VERSION ""

NS_ :

BS_:

BU_:

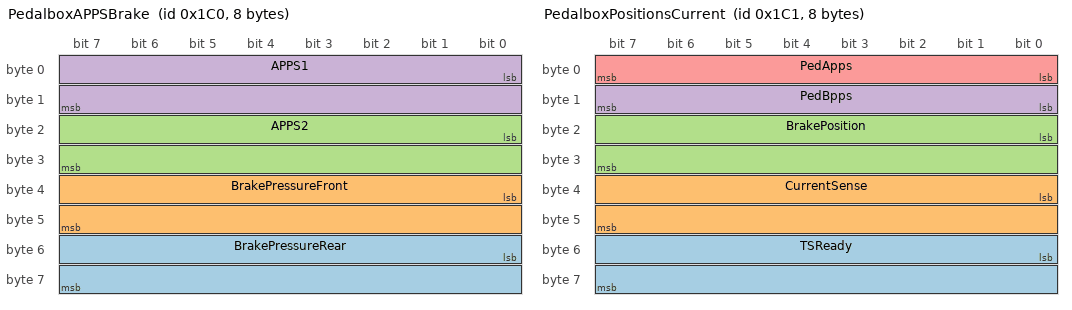
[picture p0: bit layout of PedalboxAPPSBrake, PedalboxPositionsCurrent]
BO_ 448 PedalboxAPPSBrake: 8 Vector__XXX
 SG_ BrakePressureRear : 48|16@1+ (0.001,0) [0|0] "V" Vector__XXX
 SG_ BrakePressureFront : 32|16@1+ (0.001,0) [0|0] "V" Vector__XXX
 SG_ APPS2 : 16|16@1+ (0.001,0) [0|0] "V" Vector__XXX
 SG_ APPS1 : 0|16@1+ (0.001,0) [0|0] "V" Vector__XXX

BO_ 449 PedalboxPositionsCurrent: 8 Vector__XXX
 SG_ TSReady : 48|16@1+ (0.001,0) [0|0] "V" Vector__XXX
 SG_ CurrentSense : 32|16@1+ (0.001,0) [0|0] "V" Vector__XXX
 SG_ BrakePosition : 16|16@1+ (0.001,0) [0|0] "V" Vector__XXX
 SG_ PedBpps : 8|8@1+ (1,0) [0|0] "%" Vector__XXX
 SG_ PedApps : 0|8@1+ (1,0) [0|0] "%" Vector__XXX

BO_ 450 PedalboxFaults: 8 Vector__XXX
 SG_ BrakeDrag : 16|8@1+ (1,0) [0|0] "" Vector__XXX
 SG_ HARDBRAKETHRESHOLD : 15|1@1+ (1,0) [0|0] "" Vector__XXX
 SG_ APPSANDBRAKE : 14|1@1+ (1,0) [0|0] "" Vector__XXX
 SG_ APPSIMPLAUS : 13|1@1+ (1,0) [0|0] "" Vector__XXX
 SG_ BRAKELIGHT : 12|1@1+ (1,0) [0|0] "" Vector__XXX
 SG_ BSPDHARDWARE : 11|1@1+ (1,0) [0|0] "" Vector__XXX
 SG_ BSPDOK : 10|1@1+ (1,0) [0|0] "" Vector__XXX
 SG_ CURRUV : 9|1@1+ (1,0) [0|0] "" Vector__XXX
 SG_ CURROV : 8|1@1+ (1,0) [0|0] "" Vector__XXX
 SG_ BPRUV : 7|1@1+ (1,0) [0|0] "" Vector__XXX
 SG_ BPROV : 6|1@1+ (1,0) [0|0] "" Vector__XXX
 SG_ BPFUV : 5|1@1+ (1,0) [0|0] "" Vector__XXX
 SG_ BPFOV : 4|1@1+ (1,0) [0|0] "" Vector__XXX
 SG_ APPS2UV : 3|1@1+ (1,0) [0|0] "" Vector__XXX
 SG_ APPS2OV : 2|1@1+ (1,0) [0|0] "" Vector__XXX
 SG_ APPS1UV : 1|1@1+ (1,0) [0|0] "" Vector__XXX
 SG_ APPS1OV : 0|1@1+ (1,0) [0|0] "" Vector__XXX

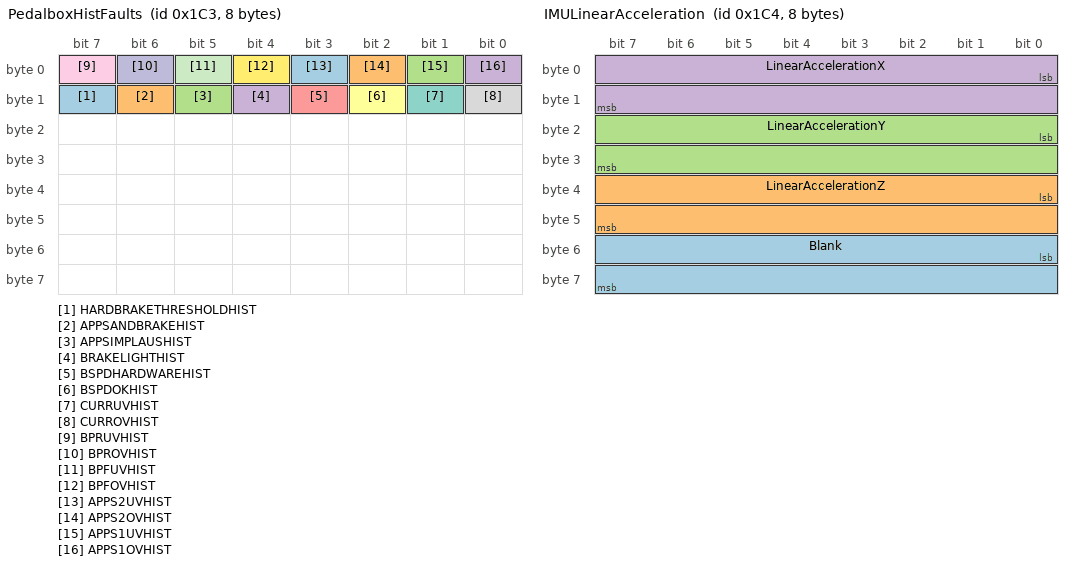
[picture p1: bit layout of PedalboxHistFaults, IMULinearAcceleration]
BO_ 451 PedalboxHistFaults: 8 Vector__XXX
 SG_ HARDBRAKETHRESHOLDHIST : 15|1@1+ (1,0) [0|0] "" Vector__XXX
 SG_ APPSANDBRAKEHIST : 14|1@1+ (1,0) [0|0] "" Vector__XXX
 SG_ APPSIMPLAUSHIST : 13|1@1+ (1,0) [0|0] "" Vector__XXX
 SG_ BRAKELIGHTHIST : 12|1@1+ (1,0) [0|0] "" Vector__XXX
 SG_ BSPDHARDWAREHIST : 11|1@1+ (1,0) [0|0] "" Vector__XXX
 SG_ BSPDOKHIST : 10|1@1+ (1,0) [0|0] "" Vector__XXX
 SG_ CURRUVHIST : 9|1@1+ (1,0) [0|0] "" Vector__XXX
 SG_ CURROVHIST : 8|1@1+ (1,0) [0|0] "" Vector__XXX
 SG_ BPRUVHIST : 7|1@1+ (1,0) [0|0] "" Vector__XXX
 SG_ BPROVHIST : 6|1@1+ (1,0) [0|0] "" Vector__XXX
 SG_ BPFUVHIST : 5|1@1+ (1,0) [0|0] "" Vector__XXX
 SG_ BPFOVHIST : 4|1@1+ (1,0) [0|0] "" Vector__XXX
 SG_ APPS2UVHIST : 3|1@1+ (1,0) [0|0] "" Vector__XXX
 SG_ APPS2OVHIST : 2|1@1+ (1,0) [0|0] "" Vector__XXX
 SG_ APPS1UVHIST : 1|1@1+ (1,0) [0|0] "" Vector__XXX
 SG_ APPS1OVHIST : 0|1@1+ (1,0) [0|0] "" Vector__XXX

BO_ 452 IMULinearAcceleration: 8 Vector__XXX
 SG_ Blank : 48|16@1- (1,0) [0|0] "" Vector__XXX
 SG_ LinearAccelerationZ : 32|16@1- (0.001,0) [0|0] "g" Vector__XXX
 SG_ LinearAccelerationY : 16|16@1- (0.001,0) [0|0] "g" Vector__XXX
 SG_ LinearAccelerationX : 0|16@1- (0.001,0) [0|0] "g" Vector__XXX

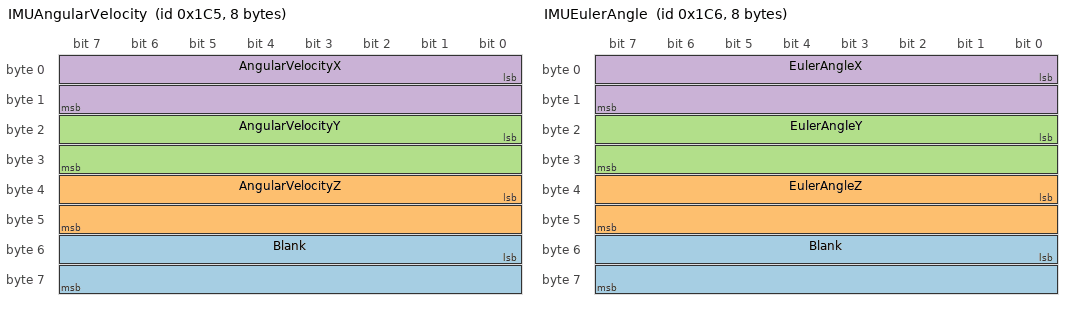
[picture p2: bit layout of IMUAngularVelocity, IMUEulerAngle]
BO_ 453 IMUAngularVelocity: 8 Vector__XXX
 SG_ Blank : 48|16@1- (1,0) [0|0] "" Vector__XXX
 SG_ AngularVelocityZ : 32|16@1- (0.1,0) [0|0] "dps" Vector__XXX
 SG_ AngularVelocityY : 16|16@1- (0.1,0) [0|0] "dps" Vector__XXX
 SG_ AngularVelocityX : 0|16@1- (0.1,0) [0|0] "dps" Vector__XXX

BO_ 454 IMUEulerAngle: 8 Vector__XXX
 SG_ Blank : 48|16@1- (1,0) [0|0] "" Vector__XXX
 SG_ EulerAngleZ : 32|16@1- (0.01,0) [0|0] "deg" Vector__XXX
 SG_ EulerAngleY : 16|16@1- (0.01,0) [0|0] "deg" Vector__XXX
 SG_ EulerAngleX : 0|16@1- (0.01,0) [0|0] "deg" Vector__XXX

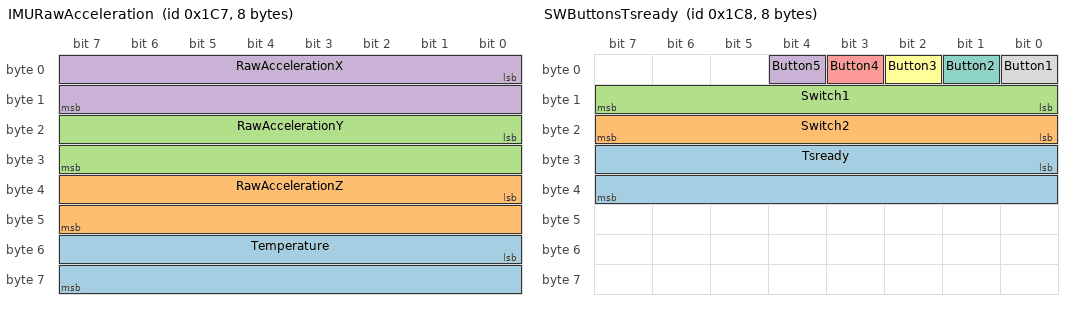
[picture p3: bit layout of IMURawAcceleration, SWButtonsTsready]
BO_ 455 IMURawAcceleration: 8 Vector__XXX
 SG_ Temperature : 48|16@1- (0.01,0) [0|0] "DegC" Vector__XXX
 SG_ RawAccelerationZ : 32|16@1- (0.001,0) [0|0] "g" Vector__XXX
 SG_ RawAccelerationY : 16|16@1- (0.001,0) [0|0] "g" Vector__XXX
 SG_ RawAccelerationX : 0|16@1- (0.001,0) [0|0] "g" Vector__XXX

BO_ 456 SWButtonsTsready: 8 Vector__XXX
 SG_ Tsready : 24|16@1+ (0.001,0) [0|0] "V" Vector__XXX
 SG_ Switch2 : 16|8@1- (1,0) [0|0] "" Vector__XXX
 SG_ Switch1 : 8|8@1- (1,0) [0|0] "" Vector__XXX
 SG_ Button5 : 4|1@1+ (1,0) [0|0] "" Vector__XXX
 SG_ Button4 : 3|1@1+ (1,0) [0|0] "" Vector__XXX
 SG_ Button3 : 2|1@1+ (1,0) [0|0] "" Vector__XXX
 SG_ Button2 : 1|1@1+ (1,0) [0|0] "" Vector__XXX
 SG_ Button1 : 0|1@1+ (1,0) [0|0] "" Vector__XXX

BO_ 457 LVMVoltageSOC: 8 Vector__XXX
 SG_ SOCEstimate : 48|16@1+ (0.1,0) [0|0] "%" Vector__XXX
 SG_ HighestTemp : 32|16@1+ (0.01,0) [0|0] "DegC" Vector__XXX
 SG_ BMSVoltage : 0|32@1+ (0.1,0) [0|0] "mV" Vector__XXX

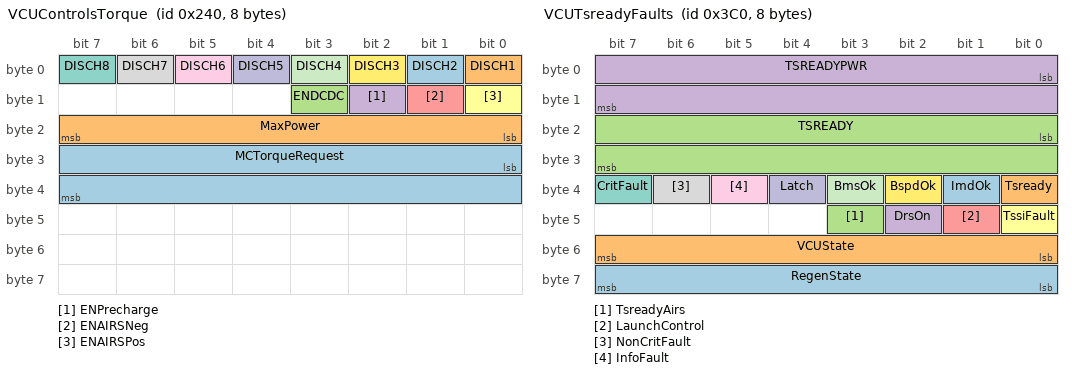
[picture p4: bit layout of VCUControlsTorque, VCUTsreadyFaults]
BO_ 576 VCUControlsTorque: 8 Vector__XXX
 SG_ MCTorqueRequest : 24|16@1- (0.1,0) [0|0] "Nm" Vector__XXX
 SG_ MaxPower : 16|8@1+ (1000,0) [0|0] "W" Vector__XXX
 SG_ ENDCDC : 11|1@1+ (1,0) [0|0] "" Vector__XXX
 SG_ ENPrecharge : 10|1@1+ (1,0) [0|0] "" Vector__XXX
 SG_ ENAIRSNeg : 9|1@1+ (1,0) [0|0] "" Vector__XXX
 SG_ ENAIRSPos : 8|1@1+ (1,0) [0|0] "" Vector__XXX
 SG_ DISCH8 : 7|1@1+ (1,0) [0|0] "" Vector__XXX
 SG_ DISCH7 : 6|1@1+ (1,0) [0|0] "" Vector__XXX
 SG_ DISCH6 : 5|1@1+ (1,0) [0|0] "" Vector__XXX
 SG_ DISCH5 : 4|1@1+ (1,0) [0|0] "" Vector__XXX
 SG_ DISCH4 : 3|1@1+ (1,0) [0|0] "" Vector__XXX
 SG_ DISCH3 : 2|1@1+ (1,0) [0|0] "" Vector__XXX
 SG_ DISCH2 : 1|1@1+ (1,0) [0|0] "" Vector__XXX
 SG_ DISCH1 : 0|1@1+ (1,0) [0|0] "" Vector__XXX

BO_ 960 VCUTsreadyFaults: 8 Vector__XXX
 SG_ RegenState : 56|8@1+ (1,0) [0|0] "" Vector__XXX
 SG_ VCUState : 48|8@1- (1,0) [0|0] "" Vector__XXX
 SG_ TsreadyAirs : 43|1@1+ (1,0) [0|0] "" Vector__XXX
 SG_ DrsOn : 42|1@1+ (1,0) [0|0] "" Vector__XXX
 SG_ LaunchControl : 41|1@1+ (1,0) [0|0] "" Vector__XXX
 SG_ TssiFault : 40|1@1+ (1,0) [0|0] "" Vector__XXX
 SG_ CritFault : 39|1@1+ (1,0) [0|0] "" Vector__XXX
 SG_ NonCritFault : 38|1@1+ (1,0) [0|0] "" Vector__XXX
 SG_ InfoFault : 37|1@1+ (1,0) [0|0] "" Vector__XXX
 SG_ Latch : 36|1@1+ (1,0) [0|0] "" Vector__XXX
 SG_ BmsOk : 35|1@1+ (1,0) [0|0] "" Vector__XXX
 SG_ BspdOk : 34|1@1+ (1,0) [0|0] "" Vector__XXX
 SG_ ImdOk : 33|1@1+ (1,0) [0|0] "" Vector__XXX
 SG_ Tsready : 32|1@1+ (1,0) [0|0] "" Vector__XXX
 SG_ TSREADY : 16|16@1+ (0.001,0) [0|0] "V" Vector__XXX
 SG_ TSREADYPWR : 0|16@1+ (0.001,0) [0|0] "V" Vector__XXX

VAL_ 960 VCUState 0 "IDLE" 1 "PRECHARGE" 2 "AIRS_CLOSED" 3 "DRIVE" ;

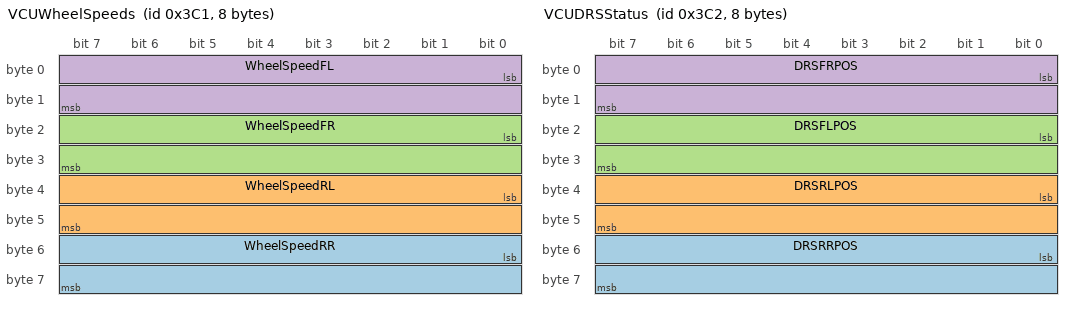
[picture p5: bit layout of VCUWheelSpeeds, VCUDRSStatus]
BO_ 961 VCUWheelSpeeds: 8 Vector__XXX
 SG_ WheelSpeedRR : 48|16@1+ (0.1,0) [0|0] "rpm" Vector__XXX
 SG_ WheelSpeedRL : 32|16@1+ (0.1,0) [0|0] "rpm" Vector__XXX
 SG_ WheelSpeedFR : 16|16@1+ (0.1,0) [0|0] "rpm" Vector__XXX
 SG_ WheelSpeedFL : 0|16@1+ (0.1,0) [0|0] "rpm" Vector__XXX

BO_ 962 VCUDRSStatus: 8 Vector__XXX
 SG_ DRSRRPOS : 48|16@1+ (0.1,0) [0|0] "Deg" Vector__XXX
 SG_ DRSRLPOS : 32|16@1+ (0.1,0) [0|0] "Deg" Vector__XXX
 SG_ DRSFLPOS : 16|16@1+ (0.1,0) [0|0] "Deg" Vector__XXX
 SG_ DRSFRPOS : 0|16@1+ (0.1,0) [0|0] "Deg" Vector__XXX

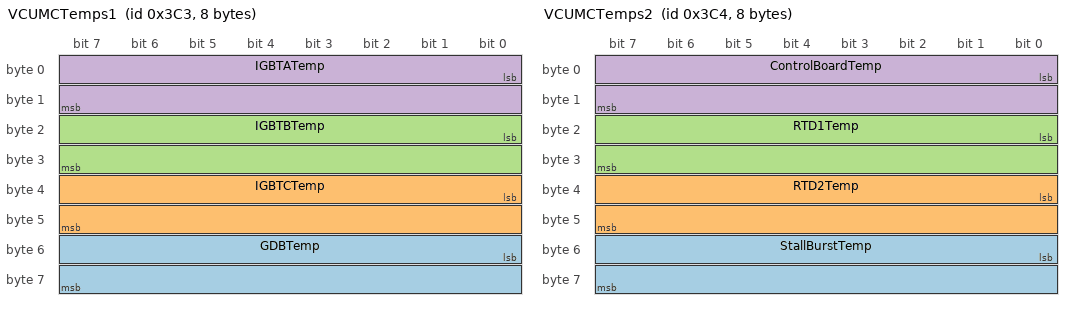
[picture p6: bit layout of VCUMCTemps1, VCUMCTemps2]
BO_ 963 VCUMCTemps1: 8 Vector__XXX
 SG_ GDBTemp : 48|16@1- (0.1,0) [0|0] "DegC" Vector__XXX
 SG_ IGBTCTemp : 32|16@1- (0.1,0) [0|0] "DegC" Vector__XXX
 SG_ IGBTBTemp : 16|16@1- (0.1,0) [0|0] "DegC" Vector__XXX
 SG_ IGBTATemp : 0|16@1- (0.1,0) [0|0] "DegC" Vector__XXX

BO_ 964 VCUMCTemps2: 8 Vector__XXX
 SG_ StallBurstTemp : 48|16@1- (0.1,0) [0|0] "DegC" Vector__XXX
 SG_ RTD2Temp : 32|16@1- (0.1,0) [0|0] "DegC" Vector__XXX
 SG_ RTD1Temp : 16|16@1- (0.1,0) [0|0] "DegC" Vector__XXX
 SG_ ControlBoardTemp : 0|16@1- (0.1,0) [0|0] "DegC" Vector__XXX

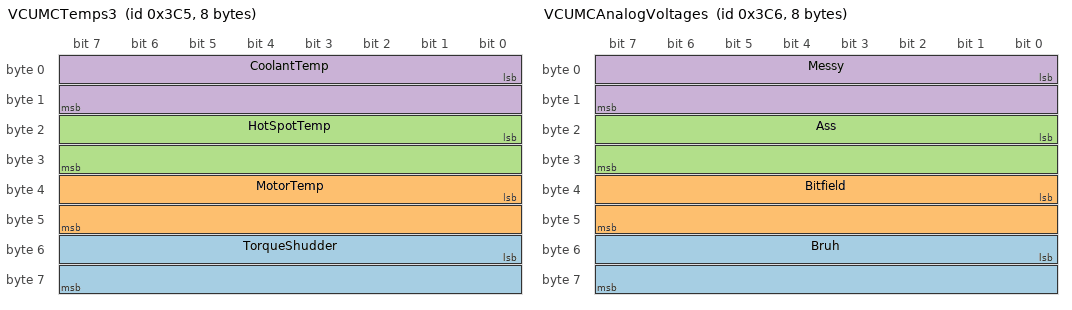
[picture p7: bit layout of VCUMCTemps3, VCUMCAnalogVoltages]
BO_ 965 VCUMCTemps3: 8 Vector__XXX
 SG_ TorqueShudder : 48|16@1- (1,0) [0|0] "" Vector__XXX
 SG_ MotorTemp : 32|16@1- (0.1,0) [0|0] "DegC" Vector__XXX
 SG_ HotSpotTemp : 16|16@1- (0.1,0) [0|0] "DegC" Vector__XXX
 SG_ CoolantTemp : 0|16@1- (0.1,0) [0|0] "DegC" Vector__XXX

BO_ 966 VCUMCAnalogVoltages: 8 Vector__XXX
 SG_ Bruh : 48|16@1+ (1,0) [0|0] "" Vector__XXX
 SG_ Bitfield : 32|16@1+ (1,0) [0|0] "" Vector__XXX
 SG_ Ass : 16|16@1+ (1,0) [0|0] "" Vector__XXX
 SG_ Messy : 0|16@1+ (1,0) [0|0] "" Vector__XXX

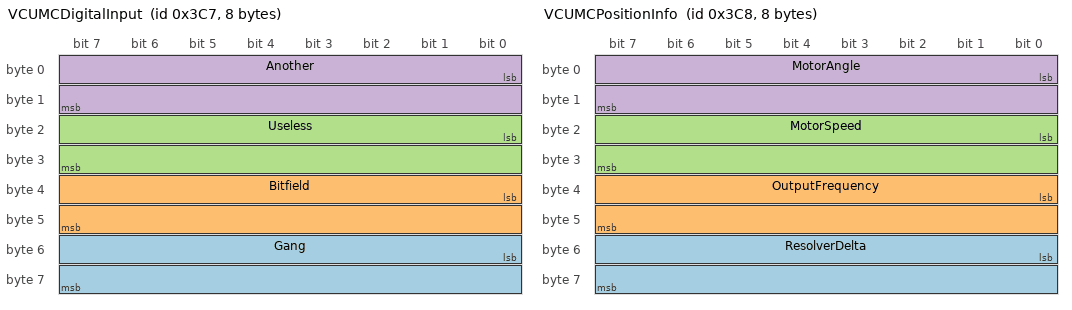
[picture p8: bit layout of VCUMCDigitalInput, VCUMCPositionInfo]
BO_ 967 VCUMCDigitalInput: 8 Vector__XXX
 SG_ Gang : 48|16@1+ (1,0) [0|0] "" Vector__XXX
 SG_ Bitfield : 32|16@1+ (1,0) [0|0] "" Vector__XXX
 SG_ Useless : 16|16@1+ (1,0) [0|0] "" Vector__XXX
 SG_ Another : 0|16@1+ (1,0) [0|0] "" Vector__XXX

BO_ 968 VCUMCPositionInfo: 8 Vector__XXX
 SG_ ResolverDelta : 48|16@1- (0.1,0) [0|0] "Deg" Vector__XXX
 SG_ OutputFrequency : 32|16@1- (0.1,0) [0|0] "Hz" Vector__XXX
 SG_ MotorSpeed : 16|16@1- (1,0) [0|0] "rpm" Vector__XXX
 SG_ MotorAngle : 0|16@1- (0.1,0) [0|0] "Deg" Vector__XXX

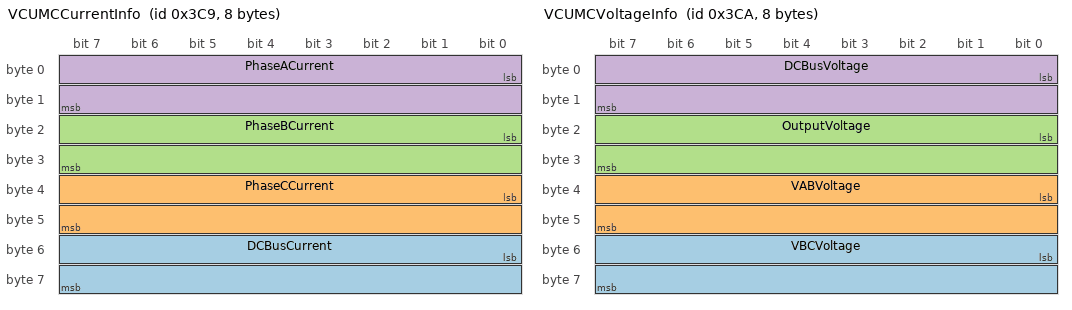
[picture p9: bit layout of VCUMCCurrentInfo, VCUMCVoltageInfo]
BO_ 969 VCUMCCurrentInfo: 8 Vector__XXX
 SG_ DCBusCurrent : 48|16@1- (0.1,0) [0|0] "A" Vector__XXX
 SG_ PhaseCCurrent : 32|16@1- (0.1,0) [0|0] "A" Vector__XXX
 SG_ PhaseBCurrent : 16|16@1- (0.1,0) [0|0] "A" Vector__XXX
 SG_ PhaseACurrent : 0|16@1- (0.1,0) [0|0] "A" Vector__XXX

BO_ 970 VCUMCVoltageInfo: 8 Vector__XXX
 SG_ VBCVoltage : 48|16@1- (0.1,0) [0|0] "V" Vector__XXX
 SG_ VABVoltage : 32|16@1- (0.1,0) [0|0] "V" Vector__XXX
 SG_ OutputVoltage : 16|16@1- (0.1,0) [0|0] "V" Vector__XXX
 SG_ DCBusVoltage : 0|16@1- (0.1,0) [0|0] "V" Vector__XXX

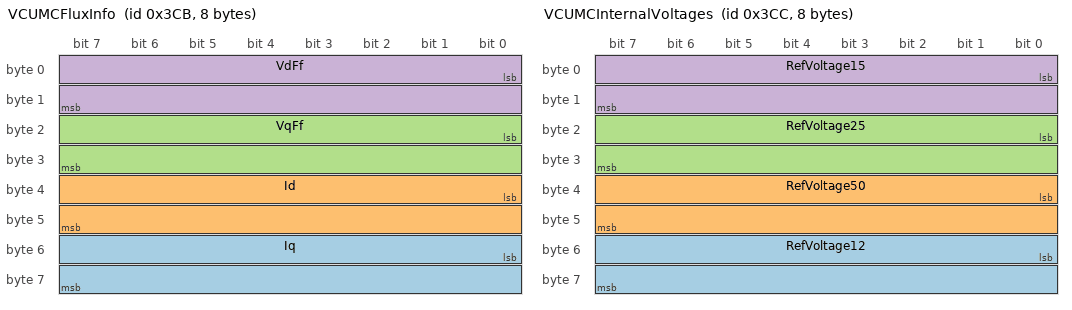
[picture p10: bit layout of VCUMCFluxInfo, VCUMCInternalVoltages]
BO_ 971 VCUMCFluxInfo: 8 Vector__XXX
 SG_ Iq : 48|16@1- (0.1,0) [0|0] "A" Vector__XXX
 SG_ Id : 32|16@1- (0.1,0) [0|0] "A" Vector__XXX
 SG_ VqFf : 16|16@1- (0.001,0) [0|0] "W" Vector__XXX
 SG_ VdFf : 0|16@1- (0.001,0) [0|0] "W" Vector__XXX

BO_ 972 VCUMCInternalVoltages: 8 Vector__XXX
 SG_ RefVoltage12 : 48|16@1- (0.01,0) [0|0] "V" Vector__XXX
 SG_ RefVoltage50 : 32|16@1- (0.01,0) [0|0] "V" Vector__XXX
 SG_ RefVoltage25 : 16|16@1- (0.01,0) [0|0] "V" Vector__XXX
 SG_ RefVoltage15 : 0|16@1- (0.01,0) [0|0] "V" Vector__XXX

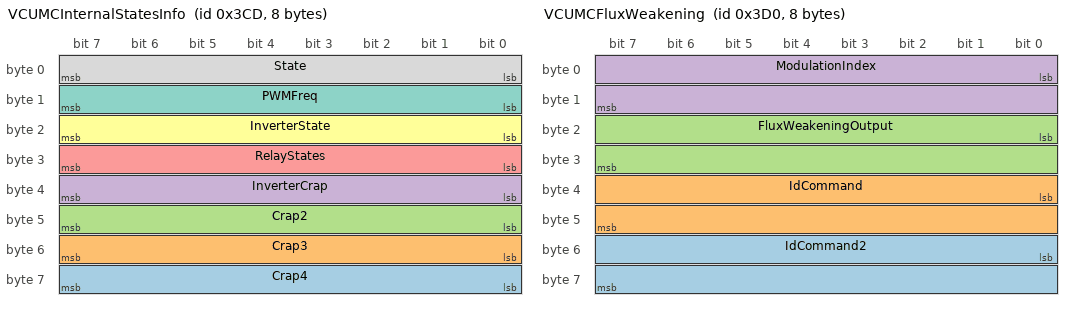
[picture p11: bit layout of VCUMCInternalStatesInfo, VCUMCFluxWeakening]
BO_ 973 VCUMCInternalStatesInfo: 8 Vector__XXX
 SG_ Crap4 : 56|8@1+ (1,0) [0|0] "" Vector__XXX
 SG_ Crap3 : 48|8@1+ (1,0) [0|0] "" Vector__XXX
 SG_ Crap2 : 40|8@1+ (1,0) [0|0] "" Vector__XXX
 SG_ InverterCrap : 32|8@1+ (1,0) [0|0] "" Vector__XXX
 SG_ RelayStates : 24|8@1+ (1,0) [0|0] "" Vector__XXX
 SG_ InverterState : 16|8@1+ (1,0) [0|0] "" Vector__XXX
 SG_ PWMFreq : 8|8@1+ (1000,0) [0|0] "Hz" Vector__XXX
 SG_ State : 0|8@1+ (1,0) [0|0] "" Vector__XXX

BO_ 974 VCUMCFaultCodes: 8 Vector__XXX
 SG_ RunFaults : 32|32@1+ (1,0) [0|0] "" Vector__XXX
 SG_ PostFaults : 0|32@1+ (1,0) [0|0] "" Vector__XXX

BO_ 975 VCUMCTorqueTimer: 8 Vector__XXX
 SG_ PowerOnTime : 32|32@1+ (1,0) [0|0] "" Vector__XXX
 SG_ TorqueFeedback : 16|16@1- (0.1,0) [0|0] "Nm" Vector__XXX
 SG_ CommandedTorque : 0|16@1- (0.1,0) [0|0] "Nm" Vector__XXX

BO_ 976 VCUMCFluxWeakening: 8 Vector__XXX
 SG_ IdCommand2 : 48|16@1- (0.1,0) [0|0] "A" Vector__XXX
 SG_ IdCommand : 32|16@1- (0.1,0) [0|0] "A" Vector__XXX
 SG_ FluxWeakeningOutput : 16|16@1- (0.1,0) [0|0] "A" Vector__XXX
 SG_ ModulationIndex : 0|16@1+ (1,0) [0|0] "" Vector__XXX

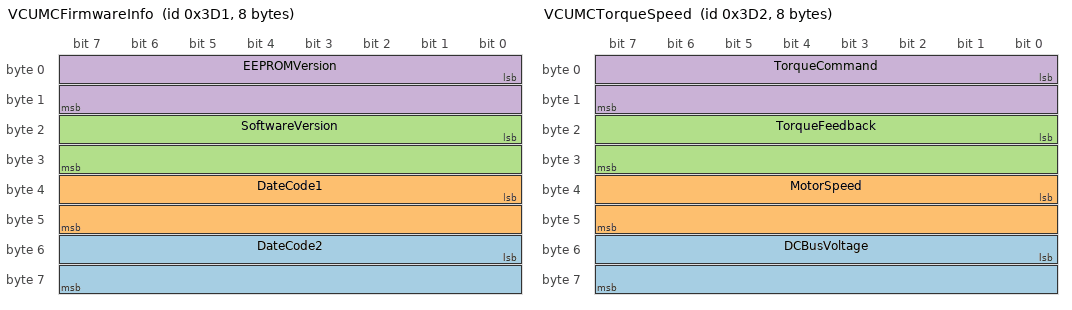
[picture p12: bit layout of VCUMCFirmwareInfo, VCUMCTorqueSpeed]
BO_ 977 VCUMCFirmwareInfo: 8 Vector__XXX
 SG_ DateCode2 : 48|16@1+ (1,0) [0|0] "" Vector__XXX
 SG_ DateCode1 : 32|16@1+ (1,0) [0|0] "" Vector__XXX
 SG_ SoftwareVersion : 16|16@1+ (1,0) [0|0] "" Vector__XXX
 SG_ EEPROMVersion : 0|16@1+ (1,0) [0|0] "" Vector__XXX

BO_ 978 VCUMCTorqueSpeed: 8 Vector__XXX
 SG_ DCBusVoltage : 48|16@1- (0.1,0) [0|0] "V" Vector__XXX
 SG_ MotorSpeed : 32|16@1- (1,0) [0|0] "rpm" Vector__XXX
 SG_ TorqueFeedback : 16|16@1- (0.1,0) [0|0] "Nm" Vector__XXX
 SG_ TorqueCommand : 0|16@1- (0.1,0) [0|0] "Nm" Vector__XXX

BO_ 979 VCUMCTorqueCapability: 8 Vector__XXX
 SG_ Unused : 32|32@1+ (1,0) [0|0] "" Vector__XXX
 SG_ AvailableRegenTorque : 16|16@1- (0.1,0) [0|0] "Nm" Vector__XXX
 SG_ AvailableTorque : 0|16@1- (0.1,0) [0|0] "Nm" Vector__XXX

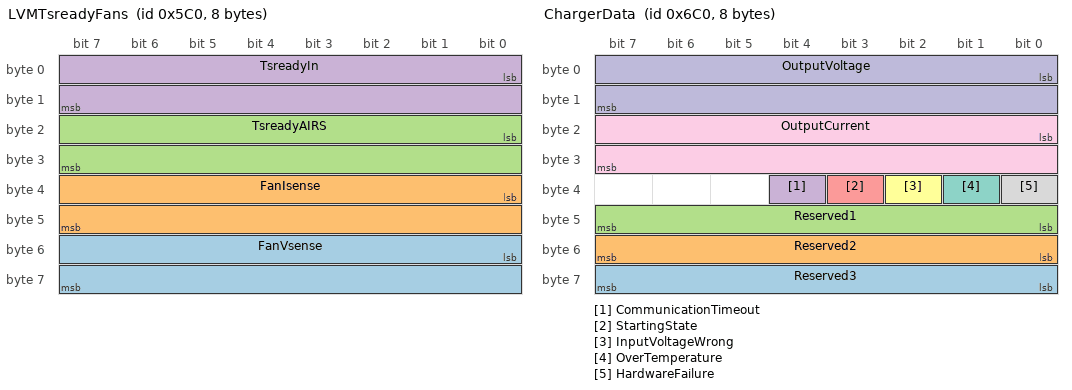
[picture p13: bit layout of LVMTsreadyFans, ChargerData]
BO_ 1472 LVMTsreadyFans: 8 Vector__XXX
 SG_ FanVsense : 48|16@1+ (0.001,0) [0|0] "V" Vector__XXX
 SG_ FanIsense : 32|16@1+ (0.001,0) [0|0] "A" Vector__XXX
 SG_ TsreadyAIRS : 16|16@1+ (0.001,0) [0|0] "V" Vector__XXX
 SG_ TsreadyIn : 0|16@1+ (0.001,0) [0|0] "V" Vector__XXX

BO_ 1728 ChargerData: 8 Vector__XXX
 SG_ Reserved3 : 56|8@1+ (1,0) [0|0] "" Vector__XXX
 SG_ Reserved2 : 48|8@1+ (1,0) [0|0] "" Vector__XXX
 SG_ Reserved1 : 40|8@1+ (1,0) [0|0] "" Vector__XXX
 SG_ CommunicationTimeout : 36|1@1+ (1,0) [0|0] "" Vector__XXX
 SG_ StartingState : 35|1@1+ (1,0) [0|0] "" Vector__XXX
 SG_ InputVoltageWrong : 34|1@1+ (1,0) [0|0] "" Vector__XXX
 SG_ OverTemperature : 33|1@1+ (1,0) [0|0] "" Vector__XXX
 SG_ HardwareFailure : 32|1@1+ (1,0) [0|0] "" Vector__XXX
 SG_ OutputCurrent : 16|16@1+ (0.1,0) [0|0] "A" Vector__XXX
 SG_ OutputVoltage : 0|16@1+ (0.1,0) [0|0] "V" Vector__XXX

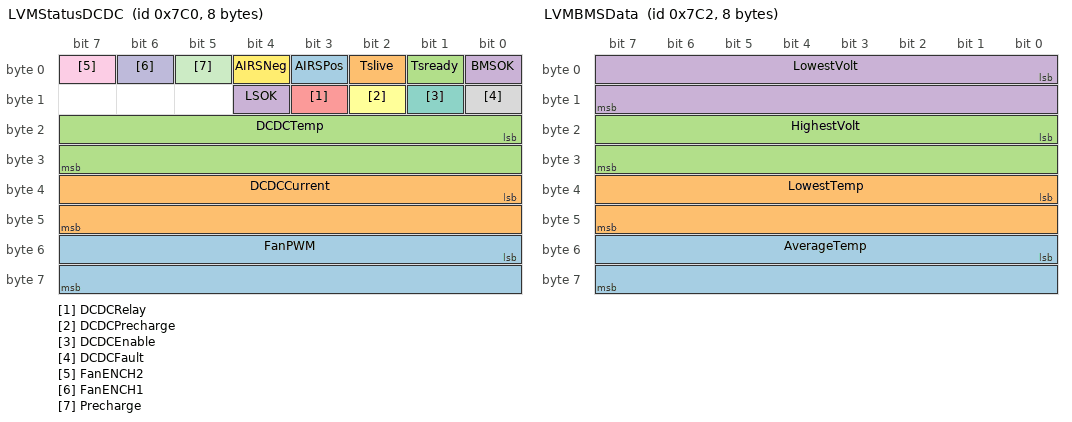
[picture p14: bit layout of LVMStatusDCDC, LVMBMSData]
BO_ 1984 LVMStatusDCDC: 8 Vector__XXX
 SG_ FanPWM : 48|16@1+ (1,0) [0|0] "%" Vector__XXX
 SG_ DCDCCurrent : 32|16@1- (0.1,0) [0|0] "A" Vector__XXX
 SG_ DCDCTemp : 16|16@1+ (0.01,0) [0|0] "DegC" Vector__XXX
 SG_ LSOK : 12|1@1+ (1,0) [0|0] "" Vector__XXX
 SG_ DCDCRelay : 11|1@1+ (1,0) [0|0] "" Vector__XXX
 SG_ DCDCPrecharge : 10|1@1+ (1,0) [0|0] "" Vector__XXX
 SG_ DCDCEnable : 9|1@1+ (1,0) [0|0] "" Vector__XXX
 SG_ DCDCFault : 8|1@1+ (1,0) [0|0] "" Vector__XXX
 SG_ FanENCH2 : 7|1@1+ (1,0) [0|0] "" Vector__XXX
 SG_ FanENCH1 : 6|1@1+ (1,0) [0|0] "" Vector__XXX
 SG_ Precharge : 5|1@1+ (1,0) [0|0] "" Vector__XXX
 SG_ AIRSNeg : 4|1@1+ (1,0) [0|0] "" Vector__XXX
 SG_ AIRSPos : 3|1@1+ (1,0) [0|0] "" Vector__XXX
 SG_ Tslive : 2|1@1+ (1,0) [0|0] "" Vector__XXX
 SG_ Tsready : 1|1@1+ (1,0) [0|0] "" Vector__XXX
 SG_ BMSOK : 0|1@1+ (1,0) [0|0] "" Vector__XXX

BO_ 1985 LVMCurrentTaskStatus: 8 Vector__XXX
 SG_ TaskStatus : 32|8@1- (1,0) [0|0] "" Vector__XXX
 SG_ Currenta : 16|16@1- (1,0) [0|0] "A" Vector__XXX
 SG_ Currentv : 0|16@1+ (0.001,0) [0|0] "V" Vector__XXX

VAL_ 1985 TaskStatus 0 "eRunning" 1 "eReady" 2 "eBlocked" 3 "eSuspended" 4 "eDeleted" 5 "eInvalid" ;

BO_ 1986 LVMBMSData: 8 Vector__XXX
 SG_ AverageTemp : 48|16@1+ (0.01,0) [0|0] "DegC" Vector__XXX
 SG_ LowestTemp : 32|16@1+ (0.01,0) [0|0] "DegC" Vector__XXX
 SG_ HighestVolt : 16|16@1+ (0.1,0) [0|0] "mV" Vector__XXX
 SG_ LowestVolt : 0|16@1+ (0.1,0) [0|0] "mV" Vector__XXX

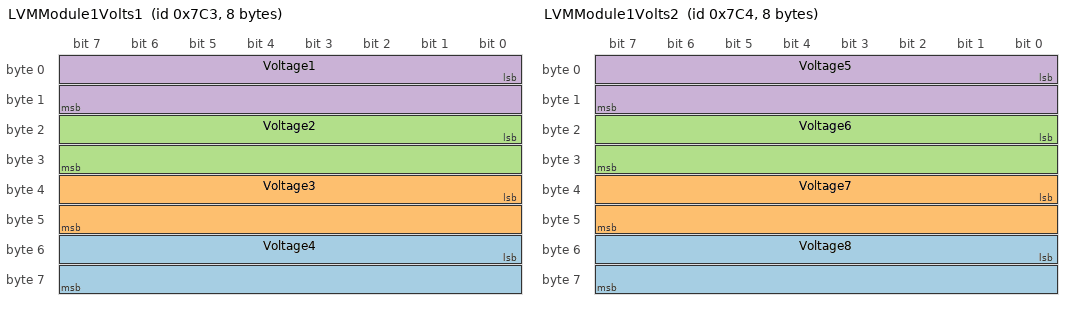
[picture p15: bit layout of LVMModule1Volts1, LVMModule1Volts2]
BO_ 1987 LVMModule1Volts1: 8 Vector__XXX
 SG_ Voltage4 : 48|16@1+ (0.1,0) [0|0] "mV" Vector__XXX
 SG_ Voltage3 : 32|16@1+ (0.1,0) [0|0] "mV" Vector__XXX
 SG_ Voltage2 : 16|16@1+ (0.1,0) [0|0] "mV" Vector__XXX
 SG_ Voltage1 : 0|16@1+ (0.1,0) [0|0] "mV" Vector__XXX

BO_ 1988 LVMModule1Volts2: 8 Vector__XXX
 SG_ Voltage8 : 48|16@1+ (0.1,0) [0|0] "mV" Vector__XXX
 SG_ Voltage7 : 32|16@1+ (0.1,0) [0|0] "mV" Vector__XXX
 SG_ Voltage6 : 16|16@1+ (0.1,0) [0|0] "mV" Vector__XXX
 SG_ Voltage5 : 0|16@1+ (0.1,0) [0|0] "mV" Vector__XXX

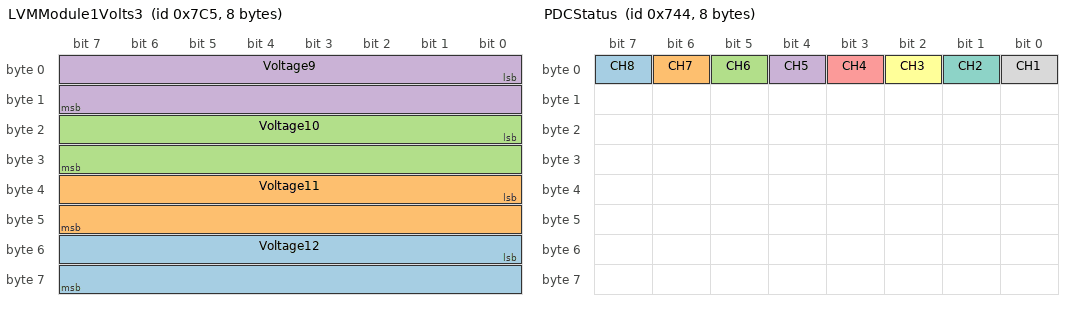
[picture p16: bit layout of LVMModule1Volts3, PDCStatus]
BO_ 1989 LVMModule1Volts3: 8 Vector__XXX
 SG_ Voltage12 : 48|16@1+ (0.1,0) [0|0] "mV" Vector__XXX
 SG_ Voltage11 : 32|16@1+ (0.1,0) [0|0] "mV" Vector__XXX
 SG_ Voltage10 : 16|16@1+ (0.1,0) [0|0] "mV" Vector__XXX
 SG_ Voltage9 : 0|16@1+ (0.1,0) [0|0] "mV" Vector__XXX

BO_ 1990 LVMModule1Volts4: 8 Vector__XXX
 SG_ Voltage16 : 48|16@1+ (0.1,0) [0|0] "mV" Vector__XXX
 SG_ Voltage15 : 32|16@1+ (0.1,0) [0|0] "mV" Vector__XXX
 SG_ Voltage14 : 16|16@1+ (0.1,0) [0|0] "mV" Vector__XXX
 SG_ Voltage13 : 0|16@1+ (0.1,0) [0|0] "mV" Vector__XXX

BO_ 1991 LVMModule2Volts1: 8 Vector__XXX
 SG_ Voltage4 : 48|16@1+ (0.1,0) [0|0] "mV" Vector__XXX
 SG_ Voltage3 : 32|16@1+ (0.1,0) [0|0] "mV" Vector__XXX
 SG_ Voltage2 : 16|16@1+ (0.1,0) [0|0] "mV" Vector__XXX
 SG_ Voltage1 : 0|16@1+ (0.1,0) [0|0] "mV" Vector__XXX

BO_ 1992 LVMModule2Volts2: 8 Vector__XXX
 SG_ Voltage8 : 48|16@1+ (0.1,0) [0|0] "mV" Vector__XXX
 SG_ Voltage7 : 32|16@1+ (0.1,0) [0|0] "mV" Vector__XXX
 SG_ Voltage6 : 16|16@1+ (0.1,0) [0|0] "mV" Vector__XXX
 SG_ Voltage5 : 0|16@1+ (0.1,0) [0|0] "mV" Vector__XXX

BO_ 1993 LVMModule2Volts3: 8 Vector__XXX
 SG_ Voltage12 : 48|16@1+ (0.1,0) [0|0] "mV" Vector__XXX
 SG_ Voltage11 : 32|16@1+ (0.1,0) [0|0] "mV" Vector__XXX
 SG_ Voltage10 : 16|16@1+ (0.1,0) [0|0] "mV" Vector__XXX
 SG_ Voltage9 : 0|16@1+ (0.1,0) [0|0] "mV" Vector__XXX

BO_ 1994 LVMModule2Volts4: 8 Vector__XXX
 SG_ Voltage16 : 48|16@1+ (0.1,0) [0|0] "mV" Vector__XXX
 SG_ Voltage15 : 32|16@1+ (0.1,0) [0|0] "mV" Vector__XXX
 SG_ Voltage14 : 16|16@1+ (0.1,0) [0|0] "mV" Vector__XXX
 SG_ Voltage13 : 0|16@1+ (0.1,0) [0|0] "mV" Vector__XXX

BO_ 1995 LVMModule3Volts1: 8 Vector__XXX
 SG_ Voltage4 : 48|16@1+ (0.1,0) [0|0] "mV" Vector__XXX
 SG_ Voltage3 : 32|16@1+ (0.1,0) [0|0] "mV" Vector__XXX
 SG_ Voltage2 : 16|16@1+ (0.1,0) [0|0] "mV" Vector__XXX
 SG_ Voltage1 : 0|16@1+ (0.1,0) [0|0] "mV" Vector__XXX

BO_ 1996 LVMModule3Volts2: 8 Vector__XXX
 SG_ Voltage8 : 48|16@1+ (0.1,0) [0|0] "mV" Vector__XXX
 SG_ Voltage7 : 32|16@1+ (0.1,0) [0|0] "mV" Vector__XXX
 SG_ Voltage6 : 16|16@1+ (0.1,0) [0|0] "mV" Vector__XXX
 SG_ Voltage5 : 0|16@1+ (0.1,0) [0|0] "mV" Vector__XXX

BO_ 1997 LVMModule3Volts3: 8 Vector__XXX
 SG_ Voltage12 : 48|16@1+ (0.1,0) [0|0] "mV" Vector__XXX
 SG_ Voltage11 : 32|16@1+ (0.1,0) [0|0] "mV" Vector__XXX
 SG_ Voltage10 : 16|16@1+ (0.1,0) [0|0] "mV" Vector__XXX
 SG_ Voltage9 : 0|16@1+ (0.1,0) [0|0] "mV" Vector__XXX

BO_ 1998 LVMModule3Volts4: 8 Vector__XXX
 SG_ Voltage16 : 48|16@1+ (0.1,0) [0|0] "mV" Vector__XXX
 SG_ Voltage15 : 32|16@1+ (0.1,0) [0|0] "mV" Vector__XXX
 SG_ Voltage14 : 16|16@1+ (0.1,0) [0|0] "mV" Vector__XXX
 SG_ Voltage13 : 0|16@1+ (0.1,0) [0|0] "mV" Vector__XXX

BO_ 1999 LVMModule4Volts1: 8 Vector__XXX
 SG_ Voltage4 : 48|16@1+ (0.1,0) [0|0] "mV" Vector__XXX
 SG_ Voltage3 : 32|16@1+ (0.1,0) [0|0] "mV" Vector__XXX
 SG_ Voltage2 : 16|16@1+ (0.1,0) [0|0] "mV" Vector__XXX
 SG_ Voltage1 : 0|16@1+ (0.1,0) [0|0] "mV" Vector__XXX

BO_ 2000 LVMModule4Volts2: 8 Vector__XXX
 SG_ Voltage8 : 48|16@1+ (0.1,0) [0|0] "mV" Vector__XXX
 SG_ Voltage7 : 32|16@1+ (0.1,0) [0|0] "mV" Vector__XXX
 SG_ Voltage6 : 16|16@1+ (0.1,0) [0|0] "mV" Vector__XXX
 SG_ Voltage5 : 0|16@1+ (0.1,0) [0|0] "mV" Vector__XXX

BO_ 2001 LVMModule4Volts3: 8 Vector__XXX
 SG_ Voltage12 : 48|16@1+ (0.1,0) [0|0] "mV" Vector__XXX
 SG_ Voltage11 : 32|16@1+ (0.1,0) [0|0] "mV" Vector__XXX
 SG_ Voltage10 : 16|16@1+ (0.1,0) [0|0] "mV" Vector__XXX
 SG_ Voltage9 : 0|16@1+ (0.1,0) [0|0] "mV" Vector__XXX

BO_ 2002 LVMModule4Volts4: 8 Vector__XXX
 SG_ Voltage16 : 48|16@1+ (0.1,0) [0|0] "mV" Vector__XXX
 SG_ Voltage15 : 32|16@1+ (0.1,0) [0|0] "mV" Vector__XXX
 SG_ Voltage14 : 16|16@1+ (0.1,0) [0|0] "mV" Vector__XXX
 SG_ Voltage13 : 0|16@1+ (0.1,0) [0|0] "mV" Vector__XXX

BO_ 2003 LVMModule5Volts1: 8 Vector__XXX
 SG_ Voltage4 : 48|16@1+ (0.1,0) [0|0] "mV" Vector__XXX
 SG_ Voltage3 : 32|16@1+ (0.1,0) [0|0] "mV" Vector__XXX
 SG_ Voltage2 : 16|16@1+ (0.1,0) [0|0] "mV" Vector__XXX
 SG_ Voltage1 : 0|16@1+ (0.1,0) [0|0] "mV" Vector__XXX

BO_ 2004 LVMModule5Volts2: 8 Vector__XXX
 SG_ Voltage8 : 48|16@1+ (0.1,0) [0|0] "mV" Vector__XXX
 SG_ Voltage7 : 32|16@1+ (0.1,0) [0|0] "mV" Vector__XXX
 SG_ Voltage6 : 16|16@1+ (0.1,0) [0|0] "mV" Vector__XXX
 SG_ Voltage5 : 0|16@1+ (0.1,0) [0|0] "mV" Vector__XXX

BO_ 2005 LVMModule5Volts3: 8 Vector__XXX
 SG_ Voltage12 : 48|16@1+ (0.1,0) [0|0] "mV" Vector__XXX
 SG_ Voltage11 : 32|16@1+ (0.1,0) [0|0] "mV" Vector__XXX
 SG_ Voltage10 : 16|16@1+ (0.1,0) [0|0] "mV" Vector__XXX
 SG_ Voltage9 : 0|16@1+ (0.1,0) [0|0] "mV" Vector__XXX

BO_ 2006 LVMModule5Volts4: 8 Vector__XXX
 SG_ Voltage16 : 48|16@1+ (0.1,0) [0|0] "mV" Vector__XXX
 SG_ Voltage15 : 32|16@1+ (0.1,0) [0|0] "mV" Vector__XXX
 SG_ Voltage14 : 16|16@1+ (0.1,0) [0|0] "mV" Vector__XXX
 SG_ Voltage13 : 0|16@1+ (0.1,0) [0|0] "mV" Vector__XXX

BO_ 2007 LVMModule6Volts1: 8 Vector__XXX
 SG_ Voltage4 : 48|16@1+ (0.1,0) [0|0] "mV" Vector__XXX
 SG_ Voltage3 : 32|16@1+ (0.1,0) [0|0] "mV" Vector__XXX
 SG_ Voltage2 : 16|16@1+ (0.1,0) [0|0] "mV" Vector__XXX
 SG_ Voltage1 : 0|16@1+ (0.1,0) [0|0] "mV" Vector__XXX

BO_ 2008 LVMModule6Volts2: 8 Vector__XXX
 SG_ Voltage8 : 48|16@1+ (0.1,0) [0|0] "mV" Vector__XXX
 SG_ Voltage7 : 32|16@1+ (0.1,0) [0|0] "mV" Vector__XXX
 SG_ Voltage6 : 16|16@1+ (0.1,0) [0|0] "mV" Vector__XXX
 SG_ Voltage5 : 0|16@1+ (0.1,0) [0|0] "mV" Vector__XXX

BO_ 2009 LVMModule6Volts3: 8 Vector__XXX
 SG_ Voltage12 : 48|16@1+ (0.1,0) [0|0] "mV" Vector__XXX
 SG_ Voltage11 : 32|16@1+ (0.1,0) [0|0] "mV" Vector__XXX
 SG_ Voltage10 : 16|16@1+ (0.1,0) [0|0] "mV" Vector__XXX
 SG_ Voltage9 : 0|16@1+ (0.1,0) [0|0] "mV" Vector__XXX

BO_ 2010 LVMModule6Volts4: 8 Vector__XXX
 SG_ Voltage16 : 48|16@1+ (0.1,0) [0|0] "mV" Vector__XXX
 SG_ Voltage15 : 32|16@1+ (0.1,0) [0|0] "mV" Vector__XXX
 SG_ Voltage14 : 16|16@1+ (0.1,0) [0|0] "mV" Vector__XXX
 SG_ Voltage13 : 0|16@1+ (0.1,0) [0|0] "mV" Vector__XXX

BO_ 2011 LVMModule1Temps1: 8 Vector__XXX
 SG_ Temp4 : 48|16@1+ (0.01,0) [0|0] "DegC" Vector__XXX
 SG_ Temp3 : 32|16@1+ (0.01,0) [0|0] "DegC" Vector__XXX
 SG_ Temp2 : 16|16@1+ (0.01,0) [0|0] "DegC" Vector__XXX
 SG_ Temp1 : 0|16@1+ (0.01,0) [0|0] "DegC" Vector__XXX

BO_ 2012 LVMModule1Temps2: 8 Vector__XXX
 SG_ Temp8 : 48|16@1+ (0.01,0) [0|0] "DegC" Vector__XXX
 SG_ Temp7 : 32|16@1+ (0.01,0) [0|0] "DegC" Vector__XXX
 SG_ Temp6 : 16|16@1+ (0.01,0) [0|0] "DegC" Vector__XXX
 SG_ Temp5 : 0|16@1+ (0.01,0) [0|0] "DegC" Vector__XXX

BO_ 2013 LVMModule1Temps3: 8 Vector__XXX
 SG_ Temp10 : 16|16@1+ (0.01,0) [0|0] "DegC" Vector__XXX
 SG_ Temp9 : 0|16@1+ (0.01,0) [0|0] "DegC" Vector__XXX

BO_ 2014 LVMModule2Temps1: 8 Vector__XXX
 SG_ Temp4 : 48|16@1+ (0.01,0) [0|0] "DegC" Vector__XXX
 SG_ Temp3 : 32|16@1+ (0.01,0) [0|0] "DegC" Vector__XXX
 SG_ Temp2 : 16|16@1+ (0.01,0) [0|0] "DegC" Vector__XXX
 SG_ Temp1 : 0|16@1+ (0.01,0) [0|0] "DegC" Vector__XXX

BO_ 2015 LVMModule2Temps2: 8 Vector__XXX
 SG_ Temp8 : 48|16@1+ (0.01,0) [0|0] "DegC" Vector__XXX
 SG_ Temp7 : 32|16@1+ (0.01,0) [0|0] "DegC" Vector__XXX
 SG_ Temp6 : 16|16@1+ (0.01,0) [0|0] "DegC" Vector__XXX
 SG_ Temp5 : 0|16@1+ (0.01,0) [0|0] "DegC" Vector__XXX

BO_ 2016 LVMModule2Temps3: 8 Vector__XXX
 SG_ Temp10 : 16|16@1+ (0.01,0) [0|0] "DegC" Vector__XXX
 SG_ Temp9 : 0|16@1+ (0.01,0) [0|0] "DegC" Vector__XXX

BO_ 2017 LVMModule3Temps1: 8 Vector__XXX
 SG_ Temp4 : 48|16@1+ (0.01,0) [0|0] "DegC" Vector__XXX
 SG_ Temp3 : 32|16@1+ (0.01,0) [0|0] "DegC" Vector__XXX
 SG_ Temp2 : 16|16@1+ (0.01,0) [0|0] "DegC" Vector__XXX
 SG_ Temp1 : 0|16@1+ (0.01,0) [0|0] "DegC" Vector__XXX

BO_ 2018 LVMModule3Temps2: 8 Vector__XXX
 SG_ Temp8 : 48|16@1+ (0.01,0) [0|0] "DegC" Vector__XXX
 SG_ Temp7 : 32|16@1+ (0.01,0) [0|0] "DegC" Vector__XXX
 SG_ Temp6 : 16|16@1+ (0.01,0) [0|0] "DegC" Vector__XXX
 SG_ Temp5 : 0|16@1+ (0.01,0) [0|0] "DegC" Vector__XXX

BO_ 2019 LVMModule3Temps3: 8 Vector__XXX
 SG_ Temp10 : 16|16@1+ (0.01,0) [0|0] "DegC" Vector__XXX
 SG_ Temp9 : 0|16@1+ (0.01,0) [0|0] "DegC" Vector__XXX

BO_ 2020 LVMModule4Temps1: 8 Vector__XXX
 SG_ Temp4 : 48|16@1+ (0.01,0) [0|0] "DegC" Vector__XXX
 SG_ Temp3 : 32|16@1+ (0.01,0) [0|0] "DegC" Vector__XXX
 SG_ Temp2 : 16|16@1+ (0.01,0) [0|0] "DegC" Vector__XXX
 SG_ Temp1 : 0|16@1+ (0.01,0) [0|0] "DegC" Vector__XXX

BO_ 2021 LVMModule4Temps2: 8 Vector__XXX
 SG_ Temp8 : 48|16@1+ (0.01,0) [0|0] "DegC" Vector__XXX
 SG_ Temp7 : 32|16@1+ (0.01,0) [0|0] "DegC" Vector__XXX
 SG_ Temp6 : 16|16@1+ (0.01,0) [0|0] "DegC" Vector__XXX
 SG_ Temp5 : 0|16@1+ (0.01,0) [0|0] "DegC" Vector__XXX

BO_ 2022 LVMModule4Temps3: 8 Vector__XXX
 SG_ Temp10 : 16|16@1+ (0.01,0) [0|0] "DegC" Vector__XXX
 SG_ Temp9 : 0|16@1+ (0.01,0) [0|0] "DegC" Vector__XXX

BO_ 2023 LVMModule5Temps1: 8 Vector__XXX
 SG_ Temp4 : 48|16@1+ (0.01,0) [0|0] "DegC" Vector__XXX
 SG_ Temp3 : 32|16@1+ (0.01,0) [0|0] "DegC" Vector__XXX
 SG_ Temp2 : 16|16@1+ (0.01,0) [0|0] "DegC" Vector__XXX
 SG_ Temp1 : 0|16@1+ (0.01,0) [0|0] "DegC" Vector__XXX

BO_ 2024 LVMModule5Temps2: 8 Vector__XXX
 SG_ Temp8 : 48|16@1+ (0.01,0) [0|0] "DegC" Vector__XXX
 SG_ Temp7 : 32|16@1+ (0.01,0) [0|0] "DegC" Vector__XXX
 SG_ Temp6 : 16|16@1+ (0.01,0) [0|0] "DegC" Vector__XXX
 SG_ Temp5 : 0|16@1+ (0.01,0) [0|0] "DegC" Vector__XXX

BO_ 2025 LVMModule5Temps3: 8 Vector__XXX
 SG_ Temp10 : 16|16@1+ (0.01,0) [0|0] "DegC" Vector__XXX
 SG_ Temp9 : 0|16@1+ (0.01,0) [0|0] "DegC" Vector__XXX

BO_ 2026 LVMModule6Temps1: 8 Vector__XXX
 SG_ Temp4 : 48|16@1+ (0.01,0) [0|0] "DegC" Vector__XXX
 SG_ Temp3 : 32|16@1+ (0.01,0) [0|0] "DegC" Vector__XXX
 SG_ Temp2 : 16|16@1+ (0.01,0) [0|0] "DegC" Vector__XXX
 SG_ Temp1 : 0|16@1+ (0.01,0) [0|0] "DegC" Vector__XXX

BO_ 2027 LVMModule6Temps2: 8 Vector__XXX
 SG_ Temp8 : 48|16@1+ (0.01,0) [0|0] "DegC" Vector__XXX
 SG_ Temp7 : 32|16@1+ (0.01,0) [0|0] "DegC" Vector__XXX
 SG_ Temp6 : 16|16@1+ (0.01,0) [0|0] "DegC" Vector__XXX
 SG_ Temp5 : 0|16@1+ (0.01,0) [0|0] "DegC" Vector__XXX

BO_ 2028 LVMModule6Temps3: 8 Vector__XXX
 SG_ Temp10 : 16|16@1+ (0.01,0) [0|0] "DegC" Vector__XXX
 SG_ Temp9 : 0|16@1+ (0.01,0) [0|0] "DegC" Vector__XXX

BO_ 1473 FrontCB1DOFPitStrpot: 8 Vector__XXX
 SG_ SteeringPot : 48|16@1+ (0.001,0) [0|0] "V" Vector__XXX
 SG_ PitotTube : 32|16@1- (1,0) [0|0] "Pa" Vector__XXX
 SG_ FL1DOF : 16|16@1+ (0.001,0) [0|0] "V" Vector__XXX
 SG_ FR1DOF : 0|16@1+ (0.001,0) [0|0] "V" Vector__XXX

BO_ 1474 FrontCBSPSG: 8 Vector__XXX
 SG_ FHShockPots : 48|16@1+ (0.001,0) [0|0] "V" Vector__XXX
 SG_ FRShockPots : 32|16@1+ (0.001,0) [0|0] "V" Vector__XXX
 SG_ FLStrainGauge : 16|16@1+ (0.001,0) [0|0] "V" Vector__XXX
 SG_ FRStrainGauge : 0|16@1+ (0.001,0) [0|0] "V" Vector__XXX

BO_ 1475 RearCBSPSG: 8 Vector__XXX
 SG_ RHShockPots : 48|16@1+ (0.001,0) [0|0] "V" Vector__XXX
 SG_ RRShockPots : 32|16@1+ (0.001,0) [0|0] "V" Vector__XXX
 SG_ RLStrainGauge : 16|16@1+ (0.001,0) [0|0] "V" Vector__XXX
 SG_ RRStrainGauge : 0|16@1+ (0.001,0) [0|0] "V" Vector__XXX

BO_ 1476 RearCBThermistorsFlowrate: 8 Vector__XXX
 SG_ FlowRate : 48|16@1+ (0.001,0) [0|0] "Lpm" Vector__XXX
 SG_ ThermistorMCOut : 32|16@1+ (0.001,0) [0|0] "V" Vector__XXX
 SG_ ThermistorRadOut : 16|16@1+ (0.001,0) [0|0] "V" Vector__XXX
 SG_ ThermistorRadIn : 0|16@1+ (0.001,0) [0|0] "V" Vector__XXX

BO_ 1477 RearCB1DOFCurrentsense: 8 Vector__XXX
 SG_ CurrentSense : 32|16@1+ (0.001,0) [0|0] "A" Vector__XXX
 SG_ RL1DOF : 16|16@1+ (0.001,0) [0|0] "V" Vector__XXX
 SG_ RR1DOF : 0|16@1+ (0.001,0) [0|0] "V" Vector__XXX

BO_ 1536 TTPMSFLPressure: 8 Vector__XXX
 SG_ GaugePressure : 55|16@0+ (1,0) [0|0] "" Vector__XXX
 SG_ Pressure : 39|16@0+ (1,0) [0|0] "" Vector__XXX
 SG_ BatteryVoltage : 23|16@0+ (1,0) [0|0] "" Vector__XXX
 SG_ SerialNumber : 7|16@0+ (1,0) [0|0] "" Vector__XXX

BO_ 1537 TTPMSFLIRTemps1: 8 Vector__XXX
 SG_ IRTempCH4 : 55|16@0+ (0.1,0) [0|0] "DegC" Vector__XXX
 SG_ IRTempCH3 : 39|16@0+ (0.1,0) [0|0] "DegC" Vector__XXX
 SG_ IRTempCH2 : 23|16@0+ (0.1,0) [0|0] "DegC" Vector__XXX
 SG_ IRTempCH1 : 7|16@0+ (0.1,0) [0|0] "DegC" Vector__XXX

BO_ 1538 TTPMSFLIRTemps2: 8 Vector__XXX
 SG_ IRTempCH8 : 55|16@0+ (0.1,0) [0|0] "DegC" Vector__XXX
 SG_ IRTempCH7 : 39|16@0+ (0.1,0) [0|0] "DegC" Vector__XXX
 SG_ IRTempCH6 : 23|16@0+ (0.1,0) [0|0] "DegC" Vector__XXX
 SG_ IRTempCH5 : 7|16@0+ (0.1,0) [0|0] "DegC" Vector__XXX

BO_ 1539 TTPMSFLIRTemps3: 8 Vector__XXX
 SG_ IRTempCH12 : 55|16@0+ (0.1,0) [0|0] "DegC" Vector__XXX
 SG_ IRTempCH11 : 39|16@0+ (0.1,0) [0|0] "DegC" Vector__XXX
 SG_ IRTempCH10 : 23|16@0+ (0.1,0) [0|0] "DegC" Vector__XXX
 SG_ IRTempCH9 : 7|16@0+ (0.1,0) [0|0] "DegC" Vector__XXX

BO_ 1540 TTPMSFLIRTemps4: 8 Vector__XXX
 SG_ IRTempCH16 : 55|16@0+ (0.1,0) [0|0] "DegC" Vector__XXX
 SG_ IRTempCH15 : 39|16@0+ (0.1,0) [0|0] "DegC" Vector__XXX
 SG_ IRTempCH14 : 23|16@0+ (0.1,0) [0|0] "DegC" Vector__XXX
 SG_ IRTempCH13 : 7|16@0+ (0.1,0) [0|0] "DegC" Vector__XXX

BO_ 1541 TTPMSFLSensorData: 8 Vector__XXX
 SG_ SensorNodeID : 55|16@0+ (1,0) [0|0] "" Vector__XXX
 SG_ SensorTemperature : 39|16@0+ (1,0) [0|0] "" Vector__XXX
 SG_ RSSI : 23|16@0+ (1,0) [0|0] "" Vector__XXX
 SG_ TransmissionCount : 7|16@0+ (1,0) [0|0] "" Vector__XXX

BO_ 1542 TTPMSFRPressure: 8 Vector__XXX
 SG_ GaugePressure : 55|16@0+ (1,0) [0|0] "" Vector__XXX
 SG_ Pressure : 39|16@0+ (1,0) [0|0] "" Vector__XXX
 SG_ BatteryVoltage : 23|16@0+ (1,0) [0|0] "" Vector__XXX
 SG_ SerialNumber : 7|16@0+ (1,0) [0|0] "" Vector__XXX

BO_ 1543 TTPMSFRIRTemps1: 8 Vector__XXX
 SG_ IRTempCH4 : 55|16@0+ (0.1,0) [0|0] "DegC" Vector__XXX
 SG_ IRTempCH3 : 39|16@0+ (0.1,0) [0|0] "DegC" Vector__XXX
 SG_ IRTempCH2 : 23|16@0+ (0.1,0) [0|0] "DegC" Vector__XXX
 SG_ IRTempCH1 : 7|16@0+ (0.1,0) [0|0] "DegC" Vector__XXX

BO_ 1544 TTPMSFRIRTemps2: 8 Vector__XXX
 SG_ IRTempCH8 : 55|16@0+ (0.1,0) [0|0] "DegC" Vector__XXX
 SG_ IRTempCH7 : 39|16@0+ (0.1,0) [0|0] "DegC" Vector__XXX
 SG_ IRTempCH6 : 23|16@0+ (0.1,0) [0|0] "DegC" Vector__XXX
 SG_ IRTempCH5 : 7|16@0+ (0.1,0) [0|0] "DegC" Vector__XXX

BO_ 1545 TTPMSFRIRTemps3: 8 Vector__XXX
 SG_ IRTempCH12 : 55|16@0+ (0.1,0) [0|0] "DegC" Vector__XXX
 SG_ IRTempCH11 : 39|16@0+ (0.1,0) [0|0] "DegC" Vector__XXX
 SG_ IRTempCH10 : 23|16@0+ (0.1,0) [0|0] "DegC" Vector__XXX
 SG_ IRTempCH9 : 7|16@0+ (0.1,0) [0|0] "DegC" Vector__XXX

BO_ 1546 TTPMSFRIRTemps4: 8 Vector__XXX
 SG_ IRTempCH16 : 55|16@0+ (0.1,0) [0|0] "DegC" Vector__XXX
 SG_ IRTempCH15 : 39|16@0+ (0.1,0) [0|0] "DegC" Vector__XXX
 SG_ IRTempCH14 : 23|16@0+ (0.1,0) [0|0] "DegC" Vector__XXX
 SG_ IRTempCH13 : 7|16@0+ (0.1,0) [0|0] "DegC" Vector__XXX

BO_ 1547 TTPMSFRSensorData: 8 Vector__XXX
 SG_ SensorNodeID : 55|16@0+ (1,0) [0|0] "" Vector__XXX
 SG_ SensorTemperature : 39|16@0+ (1,0) [0|0] "" Vector__XXX
 SG_ RSSI : 23|16@0+ (1,0) [0|0] "" Vector__XXX
 SG_ TransmissionCount : 7|16@0+ (1,0) [0|0] "" Vector__XXX

BO_ 1548 TTPMSRLPressure: 8 Vector__XXX
 SG_ GaugePressure : 55|16@0+ (1,0) [0|0] "" Vector__XXX
 SG_ Pressure : 39|16@0+ (1,0) [0|0] "" Vector__XXX
 SG_ BatteryVoltage : 23|16@0+ (1,0) [0|0] "" Vector__XXX
 SG_ SerialNumber : 7|16@0+ (1,0) [0|0] "" Vector__XXX

BO_ 1549 TTPMSRLIRTemps1: 8 Vector__XXX
 SG_ IRTempCH4 : 55|16@0+ (0.1,0) [0|0] "DegC" Vector__XXX
 SG_ IRTempCH3 : 39|16@0+ (0.1,0) [0|0] "DegC" Vector__XXX
 SG_ IRTempCH2 : 23|16@0+ (0.1,0) [0|0] "DegC" Vector__XXX
 SG_ IRTempCH1 : 7|16@0+ (0.1,0) [0|0] "DegC" Vector__XXX

BO_ 1550 TTPMSRLIRTemps2: 8 Vector__XXX
 SG_ IRTempCH8 : 55|16@0+ (0.1,0) [0|0] "DegC" Vector__XXX
 SG_ IRTempCH7 : 39|16@0+ (0.1,0) [0|0] "DegC" Vector__XXX
 SG_ IRTempCH6 : 23|16@0+ (0.1,0) [0|0] "DegC" Vector__XXX
 SG_ IRTempCH5 : 7|16@0+ (0.1,0) [0|0] "DegC" Vector__XXX

BO_ 1551 TTPMSRLIRTemps3: 8 Vector__XXX
 SG_ IRTempCH12 : 55|16@0+ (0.1,0) [0|0] "DegC" Vector__XXX
 SG_ IRTempCH11 : 39|16@0+ (0.1,0) [0|0] "DegC" Vector__XXX
 SG_ IRTempCH10 : 23|16@0+ (0.1,0) [0|0] "DegC" Vector__XXX
 SG_ IRTempCH9 : 7|16@0+ (0.1,0) [0|0] "DegC" Vector__XXX

BO_ 1552 TTPMSRLIRTemps4: 8 Vector__XXX
 SG_ IRTempCH16 : 55|16@0+ (0.1,0) [0|0] "DegC" Vector__XXX
 SG_ IRTempCH15 : 39|16@0+ (0.1,0) [0|0] "DegC" Vector__XXX
 SG_ IRTempCH14 : 23|16@0+ (0.1,0) [0|0] "DegC" Vector__XXX
 SG_ IRTempCH13 : 7|16@0+ (0.1,0) [0|0] "DegC" Vector__XXX

BO_ 1553 TTPMSRLSensorData: 8 Vector__XXX
 SG_ SensorNodeID : 55|16@0+ (1,0) [0|0] "" Vector__XXX
 SG_ SensorTemperature : 39|16@0+ (1,0) [0|0] "" Vector__XXX
 SG_ RSSI : 23|16@0+ (1,0) [0|0] "" Vector__XXX
 SG_ TransmissionCount : 7|16@0+ (1,0) [0|0] "" Vector__XXX

BO_ 1554 TTPMSRRPressure: 8 Vector__XXX
 SG_ GaugePressure : 55|16@0+ (1,0) [0|0] "" Vector__XXX
 SG_ Pressure : 39|16@0+ (1,0) [0|0] "" Vector__XXX
 SG_ BatteryVoltage : 23|16@0+ (1,0) [0|0] "" Vector__XXX
 SG_ SerialNumber : 7|16@0+ (1,0) [0|0] "" Vector__XXX

BO_ 1555 TTPMSRRIRTemps1: 8 Vector__XXX
 SG_ IRTempCH4 : 55|16@0+ (0.1,0) [0|0] "DegC" Vector__XXX
 SG_ IRTempCH3 : 39|16@0+ (0.1,0) [0|0] "DegC" Vector__XXX
 SG_ IRTempCH2 : 23|16@0+ (0.1,0) [0|0] "DegC" Vector__XXX
 SG_ IRTempCH1 : 7|16@0+ (0.1,0) [0|0] "DegC" Vector__XXX

BO_ 1556 TTPMSRRIRTemps2: 8 Vector__XXX
 SG_ IRTempCH8 : 55|16@0+ (0.1,0) [0|0] "DegC" Vector__XXX
 SG_ IRTempCH7 : 39|16@0+ (0.1,0) [0|0] "DegC" Vector__XXX
 SG_ IRTempCH6 : 23|16@0+ (0.1,0) [0|0] "DegC" Vector__XXX
 SG_ IRTempCH5 : 7|16@0+ (0.1,0) [0|0] "DegC" Vector__XXX

BO_ 1557 TTPMSRRIRTemps3: 8 Vector__XXX
 SG_ IRTempCH12 : 55|16@0+ (0.1,0) [0|0] "DegC" Vector__XXX
 SG_ IRTempCH11 : 39|16@0+ (0.1,0) [0|0] "DegC" Vector__XXX
 SG_ IRTempCH10 : 23|16@0+ (0.1,0) [0|0] "DegC" Vector__XXX
 SG_ IRTempCH9 : 7|16@0+ (0.1,0) [0|0] "DegC" Vector__XXX

BO_ 1558 TTPMSRRIRTemps4: 8 Vector__XXX
 SG_ IRTempCH16 : 55|16@0+ (0.1,0) [0|0] "DegC" Vector__XXX
 SG_ IRTempCH15 : 39|16@0+ (0.1,0) [0|0] "DegC" Vector__XXX
 SG_ IRTempCH14 : 23|16@0+ (0.1,0) [0|0] "DegC" Vector__XXX
 SG_ IRTempCH13 : 7|16@0+ (0.1,0) [0|0] "DegC" Vector__XXX

BO_ 1559 TTPMSRRSensorData: 8 Vector__XXX
 SG_ SensorNodeID : 55|16@0+ (1,0) [0|0] "" Vector__XXX
 SG_ SensorTemperature : 39|16@0+ (1,0) [0|0] "" Vector__XXX
 SG_ RSSI : 23|16@0+ (1,0) [0|0] "" Vector__XXX
 SG_ TransmissionCount : 7|16@0+ (1,0) [0|0] "" Vector__XXX

BO_ 1600 IRTireFLTemps1: 8 Vector__XXX
 SG_ IRTempCH4 : 55|16@0+ (0.1,0) [0|0] "DegC" Vector__XXX
 SG_ IRTempCH3 : 39|16@0+ (0.1,0) [0|0] "DegC" Vector__XXX
 SG_ IRTempCH2 : 23|16@0+ (0.1,0) [0|0] "DegC" Vector__XXX
 SG_ IRTempCH1 : 7|16@0+ (0.1,0) [0|0] "DegC" Vector__XXX

BO_ 1601 IRTireFLTemps2: 8 Vector__XXX
 SG_ IRTempCH8 : 55|16@0+ (0.1,0) [0|0] "DegC" Vector__XXX
 SG_ IRTempCH7 : 39|16@0+ (0.1,0) [0|0] "DegC" Vector__XXX
 SG_ IRTempCH6 : 23|16@0+ (0.1,0) [0|0] "DegC" Vector__XXX
 SG_ IRTempCH5 : 7|16@0+ (0.1,0) [0|0] "DegC" Vector__XXX

BO_ 1602 IRTireFLTemps3: 8 Vector__XXX
 SG_ IRTempCH12 : 55|16@0+ (0.1,0) [0|0] "DegC" Vector__XXX
 SG_ IRTempCH11 : 39|16@0+ (0.1,0) [0|0] "DegC" Vector__XXX
 SG_ IRTempCH10 : 23|16@0+ (0.1,0) [0|0] "DegC" Vector__XXX
 SG_ IRTempCH9 : 7|16@0+ (0.1,0) [0|0] "DegC" Vector__XXX

BO_ 1603 IRTireFLTemps4: 8 Vector__XXX
 SG_ IRTempCH16 : 55|16@0+ (0.1,0) [0|0] "DegC" Vector__XXX
 SG_ IRTempCH15 : 39|16@0+ (0.1,0) [0|0] "DegC" Vector__XXX
 SG_ IRTempCH14 : 23|16@0+ (0.1,0) [0|0] "DegC" Vector__XXX
 SG_ IRTempCH13 : 7|16@0+ (0.1,0) [0|0] "DegC" Vector__XXX

BO_ 1604 IRTireFRTemps1: 8 Vector__XXX
 SG_ IRTempCH4 : 55|16@0+ (0.1,0) [0|0] "DegC" Vector__XXX
 SG_ IRTempCH3 : 39|16@0+ (0.1,0) [0|0] "DegC" Vector__XXX
 SG_ IRTempCH2 : 23|16@0+ (0.1,0) [0|0] "DegC" Vector__XXX
 SG_ IRTempCH1 : 7|16@0+ (0.1,0) [0|0] "DegC" Vector__XXX

BO_ 1605 IRTireFRTemps2: 8 Vector__XXX
 SG_ IRTempCH8 : 55|16@0+ (0.1,0) [0|0] "DegC" Vector__XXX
 SG_ IRTempCH7 : 39|16@0+ (0.1,0) [0|0] "DegC" Vector__XXX
 SG_ IRTempCH6 : 23|16@0+ (0.1,0) [0|0] "DegC" Vector__XXX
 SG_ IRTempCH5 : 7|16@0+ (0.1,0) [0|0] "DegC" Vector__XXX

BO_ 1606 IRTireFRTemps3: 8 Vector__XXX
 SG_ IRTempCH12 : 55|16@0+ (0.1,0) [0|0] "DegC" Vector__XXX
 SG_ IRTempCH11 : 39|16@0+ (0.1,0) [0|0] "DegC" Vector__XXX
 SG_ IRTempCH10 : 23|16@0+ (0.1,0) [0|0] "DegC" Vector__XXX
 SG_ IRTempCH9 : 7|16@0+ (0.1,0) [0|0] "DegC" Vector__XXX

BO_ 1607 IRTireFRTemps4: 8 Vector__XXX
 SG_ IRTempCH16 : 55|16@0+ (0.1,0) [0|0] "DegC" Vector__XXX
 SG_ IRTempCH15 : 39|16@0+ (0.1,0) [0|0] "DegC" Vector__XXX
 SG_ IRTempCH14 : 23|16@0+ (0.1,0) [0|0] "DegC" Vector__XXX
 SG_ IRTempCH13 : 7|16@0+ (0.1,0) [0|0] "DegC" Vector__XXX

BO_ 1608 IRTireRLTemps1: 8 Vector__XXX
 SG_ IRTempCH4 : 55|16@0+ (0.1,0) [0|0] "DegC" Vector__XXX
 SG_ IRTempCH3 : 39|16@0+ (0.1,0) [0|0] "DegC" Vector__XXX
 SG_ IRTempCH2 : 23|16@0+ (0.1,0) [0|0] "DegC" Vector__XXX
 SG_ IRTempCH1 : 7|16@0+ (0.1,0) [0|0] "DegC" Vector__XXX

BO_ 1609 IRTireRLTemps2: 8 Vector__XXX
 SG_ IRTempCH8 : 55|16@0+ (0.1,0) [0|0] "DegC" Vector__XXX
 SG_ IRTempCH7 : 39|16@0+ (0.1,0) [0|0] "DegC" Vector__XXX
 SG_ IRTempCH6 : 23|16@0+ (0.1,0) [0|0] "DegC" Vector__XXX
 SG_ IRTempCH5 : 7|16@0+ (0.1,0) [0|0] "DegC" Vector__XXX

BO_ 1610 IRTireRLTemps3: 8 Vector__XXX
 SG_ IRTempCH12 : 55|16@0+ (0.1,0) [0|0] "DegC" Vector__XXX
 SG_ IRTempCH11 : 39|16@0+ (0.1,0) [0|0] "DegC" Vector__XXX
 SG_ IRTempCH10 : 23|16@0+ (0.1,0) [0|0] "DegC" Vector__XXX
 SG_ IRTempCH9 : 7|16@0+ (0.1,0) [0|0] "DegC" Vector__XXX

BO_ 1611 IRTireRLTemps4: 8 Vector__XXX
 SG_ IRTempCH16 : 55|16@0+ (0.1,0) [0|0] "DegC" Vector__XXX
 SG_ IRTempCH15 : 39|16@0+ (0.1,0) [0|0] "DegC" Vector__XXX
 SG_ IRTempCH14 : 23|16@0+ (0.1,0) [0|0] "DegC" Vector__XXX
 SG_ IRTempCH13 : 7|16@0+ (0.1,0) [0|0] "DegC" Vector__XXX

BO_ 1612 IRTireRRTemps1: 8 Vector__XXX
 SG_ IRTempCH4 : 55|16@0+ (0.1,0) [0|0] "DegC" Vector__XXX
 SG_ IRTempCH3 : 39|16@0+ (0.1,0) [0|0] "DegC" Vector__XXX
 SG_ IRTempCH2 : 23|16@0+ (0.1,0) [0|0] "DegC" Vector__XXX
 SG_ IRTempCH1 : 7|16@0+ (0.1,0) [0|0] "DegC" Vector__XXX

BO_ 1613 IRTireRRTemps2: 8 Vector__XXX
 SG_ IRTempCH8 : 55|16@0+ (0.1,0) [0|0] "DegC" Vector__XXX
 SG_ IRTempCH7 : 39|16@0+ (0.1,0) [0|0] "DegC" Vector__XXX
 SG_ IRTempCH6 : 23|16@0+ (0.1,0) [0|0] "DegC" Vector__XXX
 SG_ IRTempCH5 : 7|16@0+ (0.1,0) [0|0] "DegC" Vector__XXX

BO_ 1614 IRTireRRTemps3: 8 Vector__XXX
 SG_ IRTempCH12 : 55|16@0+ (0.1,0) [0|0] "DegC" Vector__XXX
 SG_ IRTempCH11 : 39|16@0+ (0.1,0) [0|0] "DegC" Vector__XXX
 SG_ IRTempCH10 : 23|16@0+ (0.1,0) [0|0] "DegC" Vector__XXX
 SG_ IRTempCH9 : 7|16@0+ (0.1,0) [0|0] "DegC" Vector__XXX

BO_ 1615 IRTireRRTemps4: 8 Vector__XXX
 SG_ IRTempCH16 : 55|16@0+ (0.1,0) [0|0] "DegC" Vector__XXX
 SG_ IRTempCH15 : 39|16@0+ (0.1,0) [0|0] "DegC" Vector__XXX
 SG_ IRTempCH14 : 23|16@0+ (0.1,0) [0|0] "DegC" Vector__XXX
 SG_ IRTempCH13 : 7|16@0+ (0.1,0) [0|0] "DegC" Vector__XXX

BO_ 1664 IRBrakeFLTemps1: 8 Vector__XXX
 SG_ IRTempCH4 : 55|16@0+ (0.1,0) [0|0] "DegC" Vector__XXX
 SG_ IRTempCH3 : 39|16@0+ (0.1,0) [0|0] "DegC" Vector__XXX
 SG_ IRTempCH2 : 23|16@0+ (0.1,0) [0|0] "DegC" Vector__XXX
 SG_ IRTempCH1 : 7|16@0+ (0.1,0) [0|0] "DegC" Vector__XXX

BO_ 1665 IRBrakeFLTemps2: 8 Vector__XXX
 SG_ IRTempCH8 : 55|16@0+ (0.1,0) [0|0] "DegC" Vector__XXX
 SG_ IRTempCH7 : 39|16@0+ (0.1,0) [0|0] "DegC" Vector__XXX
 SG_ IRTempCH6 : 23|16@0+ (0.1,0) [0|0] "DegC" Vector__XXX
 SG_ IRTempCH5 : 7|16@0+ (0.1,0) [0|0] "DegC" Vector__XXX

BO_ 1666 IRBrakeFLTemps3: 8 Vector__XXX
 SG_ IRTempCH12 : 55|16@0+ (0.1,0) [0|0] "DegC" Vector__XXX
 SG_ IRTempCH11 : 39|16@0+ (0.1,0) [0|0] "DegC" Vector__XXX
 SG_ IRTempCH10 : 23|16@0+ (0.1,0) [0|0] "DegC" Vector__XXX
 SG_ IRTempCH9 : 7|16@0+ (0.1,0) [0|0] "DegC" Vector__XXX

BO_ 1667 IRBrakeFLTemps4: 8 Vector__XXX
 SG_ IRTempCH16 : 55|16@0+ (0.1,0) [0|0] "DegC" Vector__XXX
 SG_ IRTempCH15 : 39|16@0+ (0.1,0) [0|0] "DegC" Vector__XXX
 SG_ IRTempCH14 : 23|16@0+ (0.1,0) [0|0] "DegC" Vector__XXX
 SG_ IRTempCH13 : 7|16@0+ (0.1,0) [0|0] "DegC" Vector__XXX

BO_ 1668 IRBrakeFLSensorTemp: 8 Vector__XXX
 SG_ SensorTemp : 7|16@0+ (1,0) [0|0] "" Vector__XXX

BO_ 1669 IRBrakeFRTemps1: 8 Vector__XXX
 SG_ IRTempCH4 : 55|16@0+ (0.1,0) [0|0] "DegC" Vector__XXX
 SG_ IRTempCH3 : 39|16@0+ (0.1,0) [0|0] "DegC" Vector__XXX
 SG_ IRTempCH2 : 23|16@0+ (0.1,0) [0|0] "DegC" Vector__XXX
 SG_ IRTempCH1 : 7|16@0+ (0.1,0) [0|0] "DegC" Vector__XXX

BO_ 1670 IRBrakeFRTemps2: 8 Vector__XXX
 SG_ IRTempCH8 : 55|16@0+ (0.1,0) [0|0] "DegC" Vector__XXX
 SG_ IRTempCH7 : 39|16@0+ (0.1,0) [0|0] "DegC" Vector__XXX
 SG_ IRTempCH6 : 23|16@0+ (0.1,0) [0|0] "DegC" Vector__XXX
 SG_ IRTempCH5 : 7|16@0+ (0.1,0) [0|0] "DegC" Vector__XXX

BO_ 1671 IRBrakeFRTemps3: 8 Vector__XXX
 SG_ IRTempCH12 : 55|16@0+ (0.1,0) [0|0] "DegC" Vector__XXX
 SG_ IRTempCH11 : 39|16@0+ (0.1,0) [0|0] "DegC" Vector__XXX
 SG_ IRTempCH10 : 23|16@0+ (0.1,0) [0|0] "DegC" Vector__XXX
 SG_ IRTempCH9 : 7|16@0+ (0.1,0) [0|0] "DegC" Vector__XXX

BO_ 1672 IRBrakeFRTemps4: 8 Vector__XXX
 SG_ IRTempCH16 : 55|16@0+ (0.1,0) [0|0] "DegC" Vector__XXX
 SG_ IRTempCH15 : 39|16@0+ (0.1,0) [0|0] "DegC" Vector__XXX
 SG_ IRTempCH14 : 23|16@0+ (0.1,0) [0|0] "DegC" Vector__XXX
 SG_ IRTempCH13 : 7|16@0+ (0.1,0) [0|0] "DegC" Vector__XXX

BO_ 1673 IRBrakeFRSensorTemp: 8 Vector__XXX
 SG_ SensorTemp : 7|16@0+ (1,0) [0|0] "" Vector__XXX

BO_ 1674 IRBrakeRLTemps1: 8 Vector__XXX
 SG_ IRTempCH4 : 55|16@0+ (0.1,0) [0|0] "DegC" Vector__XXX
 SG_ IRTempCH3 : 39|16@0+ (0.1,0) [0|0] "DegC" Vector__XXX
 SG_ IRTempCH2 : 23|16@0+ (0.1,0) [0|0] "DegC" Vector__XXX
 SG_ IRTempCH1 : 7|16@0+ (0.1,0) [0|0] "DegC" Vector__XXX

BO_ 1675 IRBrakeRLTemps2: 8 Vector__XXX
 SG_ IRTempCH8 : 55|16@0+ (0.1,0) [0|0] "DegC" Vector__XXX
 SG_ IRTempCH7 : 39|16@0+ (0.1,0) [0|0] "DegC" Vector__XXX
 SG_ IRTempCH6 : 23|16@0+ (0.1,0) [0|0] "DegC" Vector__XXX
 SG_ IRTempCH5 : 7|16@0+ (0.1,0) [0|0] "DegC" Vector__XXX

BO_ 1676 IRBrakeRLTemps3: 8 Vector__XXX
 SG_ IRTempCH12 : 55|16@0+ (0.1,0) [0|0] "DegC" Vector__XXX
 SG_ IRTempCH11 : 39|16@0+ (0.1,0) [0|0] "DegC" Vector__XXX
 SG_ IRTempCH10 : 23|16@0+ (0.1,0) [0|0] "DegC" Vector__XXX
 SG_ IRTempCH9 : 7|16@0+ (0.1,0) [0|0] "DegC" Vector__XXX

BO_ 1677 IRBrakeRLTemps4: 8 Vector__XXX
 SG_ IRTempCH16 : 55|16@0+ (0.1,0) [0|0] "DegC" Vector__XXX
 SG_ IRTempCH15 : 39|16@0+ (0.1,0) [0|0] "DegC" Vector__XXX
 SG_ IRTempCH14 : 23|16@0+ (0.1,0) [0|0] "DegC" Vector__XXX
 SG_ IRTempCH13 : 7|16@0+ (0.1,0) [0|0] "DegC" Vector__XXX

BO_ 1678 IRBrakeRLSensorTemp: 8 Vector__XXX
 SG_ SensorTemp : 7|16@0+ (1,0) [0|0] "" Vector__XXX

BO_ 1679 IRBrakeRRTemps1: 8 Vector__XXX
 SG_ IRTempCH4 : 55|16@0+ (0.1,0) [0|0] "DegC" Vector__XXX
 SG_ IRTempCH3 : 39|16@0+ (0.1,0) [0|0] "DegC" Vector__XXX
 SG_ IRTempCH2 : 23|16@0+ (0.1,0) [0|0] "DegC" Vector__XXX
 SG_ IRTempCH1 : 7|16@0+ (0.1,0) [0|0] "DegC" Vector__XXX

BO_ 1680 IRBrakeRRTemps2: 8 Vector__XXX
 SG_ IRTempCH8 : 55|16@0+ (0.1,0) [0|0] "DegC" Vector__XXX
 SG_ IRTempCH7 : 39|16@0+ (0.1,0) [0|0] "DegC" Vector__XXX
 SG_ IRTempCH6 : 23|16@0+ (0.1,0) [0|0] "DegC" Vector__XXX
 SG_ IRTempCH5 : 7|16@0+ (0.1,0) [0|0] "DegC" Vector__XXX

BO_ 1681 IRBrakeRRTemps3: 8 Vector__XXX
 SG_ IRTempCH12 : 55|16@0+ (0.1,0) [0|0] "DegC" Vector__XXX
 SG_ IRTempCH11 : 39|16@0+ (0.1,0) [0|0] "DegC" Vector__XXX
 SG_ IRTempCH10 : 23|16@0+ (0.1,0) [0|0] "DegC" Vector__XXX
 SG_ IRTempCH9 : 7|16@0+ (0.1,0) [0|0] "DegC" Vector__XXX

BO_ 1682 IRBrakeRRTemps4: 8 Vector__XXX
 SG_ IRTempCH16 : 55|16@0+ (0.1,0) [0|0] "DegC" Vector__XXX
 SG_ IRTempCH15 : 39|16@0+ (0.1,0) [0|0] "DegC" Vector__XXX
 SG_ IRTempCH14 : 23|16@0+ (0.1,0) [0|0] "DegC" Vector__XXX
 SG_ IRTempCH13 : 7|16@0+ (0.1,0) [0|0] "DegC" Vector__XXX

BO_ 1683 IRBrakeRRSensorTemp: 8 Vector__XXX
 SG_ SensorTemp : 7|16@0+ (1,0) [0|0] "" Vector__XXX

BO_ 1729 LiveTelemetryStatus: 8 Vector__XXX
 SG_ Ms : 48|16@1+ (0.001,0) [0|0] "s" Vector__XXX
 SG_ Time : 16|32@1+ (1,0) [0|0] "s" Vector__XXX
 SG_ Users : 8|8@1+ (1,0) [0|0] "" Vector__XXX
 SG_ State : 0|8@1- (1,0) [0|0] "" Vector__XXX

VAL_ 1729 State 0 "STARTUP" 1 "NETWORK_UP" 2 "SERVING_CLIENTS" 3 "FULL_CLIENTS" ;

BO_ 1792 AerocanMessage1: 8 Vector__XXX
 SG_ Pressure4 : 48|16@1- (1,0) [0|0] "Pa" Vector__XXX
 SG_ Pressure3 : 32|16@1- (1,0) [0|0] "Pa" Vector__XXX
 SG_ Pressure2 : 16|16@1- (1,0) [0|0] "Pa" Vector__XXX
 SG_ Pressure1 : 0|16@1- (1,0) [0|0] "Pa" Vector__XXX

BO_ 1793 AerocanMessage2: 8 Vector__XXX
 SG_ Pressure4 : 48|16@1- (1,0) [0|0] "Pa" Vector__XXX
 SG_ Pressure3 : 32|16@1- (1,0) [0|0] "Pa" Vector__XXX
 SG_ Pressure2 : 16|16@1- (1,0) [0|0] "Pa" Vector__XXX
 SG_ Pressure1 : 0|16@1- (1,0) [0|0] "Pa" Vector__XXX

BO_ 1794 AerocanMessage3: 8 Vector__XXX
 SG_ Pressure4 : 48|16@1- (1,0) [0|0] "Pa" Vector__XXX
 SG_ Pressure3 : 32|16@1- (1,0) [0|0] "Pa" Vector__XXX
 SG_ Pressure2 : 16|16@1- (1,0) [0|0] "Pa" Vector__XXX
 SG_ Pressure1 : 0|16@1- (1,0) [0|0] "Pa" Vector__XXX

BO_ 1795 AerocanMessage4: 8 Vector__XXX
 SG_ Pressure4 : 48|16@1- (1,0) [0|0] "Pa" Vector__XXX
 SG_ Pressure3 : 32|16@1- (1,0) [0|0] "Pa" Vector__XXX
 SG_ Pressure2 : 16|16@1- (1,0) [0|0] "Pa" Vector__XXX
 SG_ Pressure1 : 0|16@1- (1,0) [0|0] "Pa" Vector__XXX

BO_ 1796 AerocanMessage5: 8 Vector__XXX
 SG_ Pressure4 : 48|16@1- (1,0) [0|0] "Pa" Vector__XXX
 SG_ Pressure3 : 32|16@1- (1,0) [0|0] "Pa" Vector__XXX
 SG_ Pressure2 : 16|16@1- (1,0) [0|0] "Pa" Vector__XXX
 SG_ Pressure1 : 0|16@1- (1,0) [0|0] "Pa" Vector__XXX

BO_ 1797 AerocanMessage6: 8 Vector__XXX
 SG_ Pressure4 : 48|16@1- (1,0) [0|0] "Pa" Vector__XXX
 SG_ Pressure3 : 32|16@1- (1,0) [0|0] "Pa" Vector__XXX
 SG_ Pressure2 : 16|16@1- (1,0) [0|0] "Pa" Vector__XXX
 SG_ Pressure1 : 0|16@1- (1,0) [0|0] "Pa" Vector__XXX

BO_ 1798 AerocanMessage7: 8 Vector__XXX
 SG_ Pressure4 : 48|16@1- (1,0) [0|0] "Pa" Vector__XXX
 SG_ Pressure3 : 32|16@1- (1,0) [0|0] "Pa" Vector__XXX
 SG_ Pressure2 : 16|16@1- (1,0) [0|0] "Pa" Vector__XXX
 SG_ Pressure1 : 0|16@1- (1,0) [0|0] "Pa" Vector__XXX

BO_ 1799 AerocanMessage8: 8 Vector__XXX
 SG_ Pressure4 : 48|16@1- (1,0) [0|0] "Pa" Vector__XXX
 SG_ Pressure3 : 32|16@1- (1,0) [0|0] "Pa" Vector__XXX
 SG_ Pressure2 : 16|16@1- (1,0) [0|0] "Pa" Vector__XXX
 SG_ Pressure1 : 0|16@1- (1,0) [0|0] "Pa" Vector__XXX

BO_ 1800 AerocanMessage9: 8 Vector__XXX
 SG_ Pressure4 : 48|16@1- (1,0) [0|0] "Pa" Vector__XXX
 SG_ Pressure3 : 32|16@1- (1,0) [0|0] "Pa" Vector__XXX
 SG_ Pressure2 : 16|16@1- (1,0) [0|0] "Pa" Vector__XXX
 SG_ Pressure1 : 0|16@1- (1,0) [0|0] "Pa" Vector__XXX

BO_ 1801 AerocanMessage10: 8 Vector__XXX
 SG_ Pressure4 : 48|16@1- (1,0) [0|0] "Pa" Vector__XXX
 SG_ Pressure3 : 32|16@1- (1,0) [0|0] "Pa" Vector__XXX
 SG_ Pressure2 : 16|16@1- (1,0) [0|0] "Pa" Vector__XXX
 SG_ Pressure1 : 0|16@1- (1,0) [0|0] "Pa" Vector__XXX

BO_ 1802 AerocanMessage11: 8 Vector__XXX
 SG_ Pressure4 : 48|16@1- (1,0) [0|0] "Pa" Vector__XXX
 SG_ Pressure3 : 32|16@1- (1,0) [0|0] "Pa" Vector__XXX
 SG_ Pressure2 : 16|16@1- (1,0) [0|0] "Pa" Vector__XXX
 SG_ Pressure1 : 0|16@1- (1,0) [0|0] "Pa" Vector__XXX

BO_ 1803 AerocanMessage12: 8 Vector__XXX
 SG_ Pressure4 : 48|16@1- (1,0) [0|0] "Pa" Vector__XXX
 SG_ Pressure3 : 32|16@1- (1,0) [0|0] "Pa" Vector__XXX
 SG_ Pressure2 : 16|16@1- (1,0) [0|0] "Pa" Vector__XXX
 SG_ Pressure1 : 0|16@1- (1,0) [0|0] "Pa" Vector__XXX

BO_ 1856 PDCChannels12: 8 Vector__XXX
 SG_ Current2 : 48|16@1+ (0.001,0) [0|0] "A" Vector__XXX
 SG_ Voltage2 : 32|16@1+ (0.001,0) [0|0] "V" Vector__XXX
 SG_ Current1 : 16|16@1+ (0.001,0) [0|0] "A" Vector__XXX
 SG_ Voltage1 : 0|16@1+ (0.001,0) [0|0] "V" Vector__XXX

BO_ 1857 PDCChannels34: 8 Vector__XXX
 SG_ Current4 : 48|16@1+ (0.001,0) [0|0] "A" Vector__XXX
 SG_ Voltage4 : 32|16@1+ (0.001,0) [0|0] "V" Vector__XXX
 SG_ Current3 : 16|16@1+ (0.001,0) [0|0] "A" Vector__XXX
 SG_ Voltage3 : 0|16@1+ (0.001,0) [0|0] "V" Vector__XXX

BO_ 1858 PDCChannels56: 8 Vector__XXX
 SG_ Current6 : 48|16@1+ (0.001,0) [0|0] "A" Vector__XXX
 SG_ Voltage6 : 32|16@1+ (0.001,0) [0|0] "V" Vector__XXX
 SG_ Current5 : 16|16@1+ (0.001,0) [0|0] "A" Vector__XXX
 SG_ Voltage5 : 0|16@1+ (0.001,0) [0|0] "V" Vector__XXX

BO_ 1859 PDCChannels78: 8 Vector__XXX
 SG_ Current8 : 48|16@1+ (0.001,0) [0|0] "A" Vector__XXX
 SG_ Voltage8 : 32|16@1+ (0.001,0) [0|0] "V" Vector__XXX
 SG_ Current7 : 16|16@1+ (0.001,0) [0|0] "A" Vector__XXX
 SG_ Voltage7 : 0|16@1+ (0.001,0) [0|0] "V" Vector__XXX

BO_ 1860 PDCStatus: 8 Vector__XXX
 SG_ CH8 : 7|1@1+ (1,0) [0|0] "" Vector__XXX
 SG_ CH7 : 6|1@1+ (1,0) [0|0] "" Vector__XXX
 SG_ CH6 : 5|1@1+ (1,0) [0|0] "" Vector__XXX
 SG_ CH5 : 4|1@1+ (1,0) [0|0] "" Vector__XXX
 SG_ CH4 : 3|1@1+ (1,0) [0|0] "" Vector__XXX
 SG_ CH3 : 2|1@1+ (1,0) [0|0] "" Vector__XXX
 SG_ CH2 : 1|1@1+ (1,0) [0|0] "" Vector__XXX
 SG_ CH1 : 0|1@1+ (1,0) [0|0] "" Vector__XXX

BO_ 1920 Laser1: 8 Vector__XXX
 SG_ Unused : 55|16@0+ (1,0) [0|0] "" Vector__XXX
 SG_ Temperature : 39|16@0+ (1,0) [0|0] "degC" Vector__XXX
 SG_ RawRideHeight : 23|16@0+ (1,0) [0|0] "" Vector__XXX
 SG_ RideHeight : 7|16@0+ (0.01,0) [0|0] "mm" Vector__XXX

BO_ 1921 Laser2: 8 Vector__XXX
 SG_ Unused : 55|16@0+ (1,0) [0|0] "" Vector__XXX
 SG_ Temperature : 39|16@0+ (1,0) [0|0] "degC" Vector__XXX
 SG_ RawRideHeight : 23|16@0+ (1,0) [0|0] "" Vector__XXX
 SG_ RideHeight : 7|16@0+ (0.01,0) [0|0] "mm" Vector__XXX

BO_ 1922 Laser3: 8 Vector__XXX
 SG_ Unused : 55|16@0+ (1,0) [0|0] "" Vector__XXX
 SG_ Temperature : 39|16@0+ (1,0) [0|0] "degC" Vector__XXX
 SG_ RawRideHeight : 23|16@0+ (1,0) [0|0] "" Vector__XXX
 SG_ RideHeight : 7|16@0+ (0.01,0) [0|0] "mm" Vector__XXX

BO_ 1923 Laser4: 8 Vector__XXX
 SG_ Unused : 55|16@0+ (1,0) [0|0] "" Vector__XXX
 SG_ Temperature : 39|16@0+ (1,0) [0|0] "degC" Vector__XXX
 SG_ RawRideHeight : 23|16@0+ (1,0) [0|0] "" Vector__XXX
 SG_ RideHeight : 7|16@0+ (0.01,0) [0|0] "mm" Vector__XXX

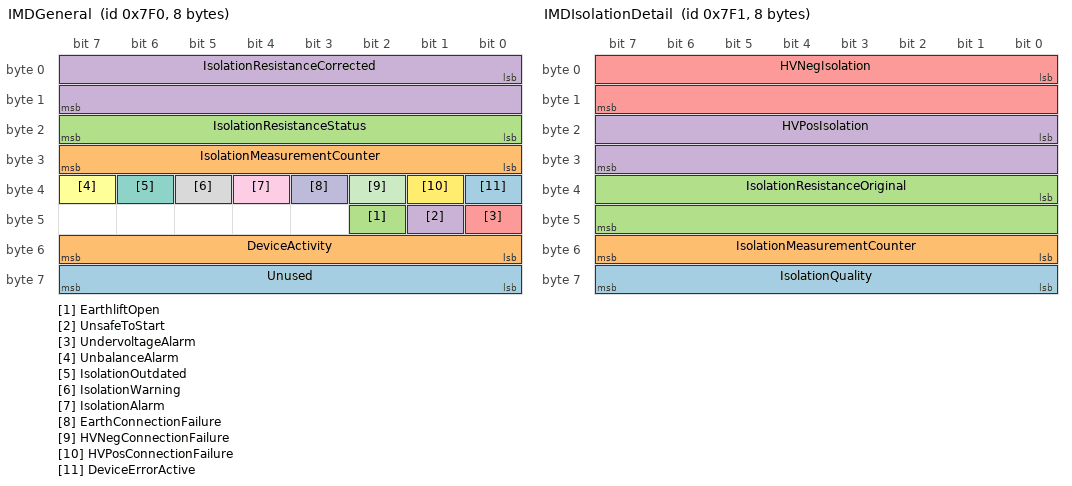
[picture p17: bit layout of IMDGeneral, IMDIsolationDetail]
BO_ 2032 IMDGeneral: 8 Vector__XXX
 SG_ Unused : 56|8@1+ (1,0) [0|0] "" Vector__XXX
 SG_ DeviceActivity : 48|8@1+ (1,0) [0|0] "" Vector__XXX
 SG_ EarthliftOpen : 42|1@1+ (1,0) [0|0] "" Vector__XXX
 SG_ UnsafeToStart : 41|1@1+ (1,0) [0|0] "" Vector__XXX
 SG_ UndervoltageAlarm : 40|1@1+ (1,0) [0|0] "" Vector__XXX
 SG_ UnbalanceAlarm : 39|1@1+ (1,0) [0|0] "" Vector__XXX
 SG_ IsolationOutdated : 38|1@1+ (1,0) [0|0] "" Vector__XXX
 SG_ IsolationWarning : 37|1@1+ (1,0) [0|0] "" Vector__XXX
 SG_ IsolationAlarm : 36|1@1+ (1,0) [0|0] "" Vector__XXX
 SG_ EarthConnectionFailure : 35|1@1+ (1,0) [0|0] "" Vector__XXX
 SG_ HVNegConnectionFailure : 34|1@1+ (1,0) [0|0] "" Vector__XXX
 SG_ HVPosConnectionFailure : 33|1@1+ (1,0) [0|0] "" Vector__XXX
 SG_ DeviceErrorActive : 32|1@1+ (1,0) [0|0] "" Vector__XXX
 SG_ IsolationMeasurementCounter : 24|8@1+ (1,0) [0|0] "" Vector__XXX
 SG_ IsolationResistanceStatus : 16|8@1+ (1,0) [0|0] "" Vector__XXX
 SG_ IsolationResistanceCorrected : 0|16@1+ (1000,0) [0|0] "Ohm" Vector__XXX

BO_ 2033 IMDIsolationDetail: 8 Vector__XXX
 SG_ IsolationQuality : 56|8@1+ (1,0) [0|0] "%" Vector__XXX
 SG_ IsolationMeasurementCounter : 48|8@1+ (1,0) [0|0] "" Vector__XXX
 SG_ IsolationResistanceOriginal : 32|16@1+ (1,0) [0|0] "" Vector__XXX
 SG_ HVPosIsolation : 16|16@1+ (1000,0) [0|0] "Ohm" Vector__XXX
 SG_ HVNegIsolation : 0|16@1+ (1000,0) [0|0] "Ohm" Vector__XXX

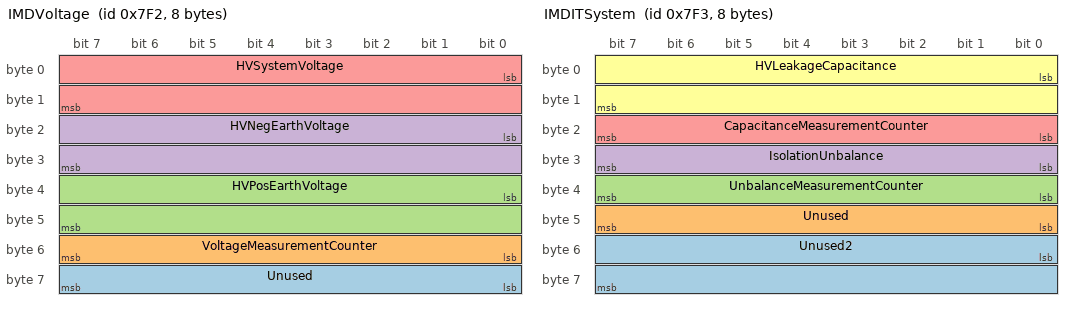
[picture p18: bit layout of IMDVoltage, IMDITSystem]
BO_ 2034 IMDVoltage: 8 Vector__XXX
 SG_ Unused : 56|8@1+ (1,0) [0|0] "" Vector__XXX
 SG_ VoltageMeasurementCounter : 48|8@1+ (1,0) [0|0] "" Vector__XXX
 SG_ HVPosEarthVoltage : 32|16@1+ (1,0) [0|0] "V" Vector__XXX
 SG_ HVNegEarthVoltage : 16|16@1+ (1,0) [0|0] "V" Vector__XXX
 SG_ HVSystemVoltage : 0|16@1+ (1,0) [0|0] "V" Vector__XXX

BO_ 2035 IMDITSystem: 8 Vector__XXX
 SG_ Unused2 : 48|16@1+ (1,0) [0|0] "" Vector__XXX
 SG_ Unused : 40|8@1+ (1,0) [0|0] "" Vector__XXX
 SG_ UnbalanceMeasurementCounter : 32|8@1+ (1,0) [0|0] "" Vector__XXX
 SG_ IsolationUnbalance : 24|8@1+ (1,0) [0|0] "%" Vector__XXX
 SG_ CapacitanceMeasurementCounter : 16|8@1+ (1,0) [0|0] "" Vector__XXX
 SG_ HVLeakageCapacitance : 0|16@1+ (0.1,0) [0|0] "uF" Vector__XXX

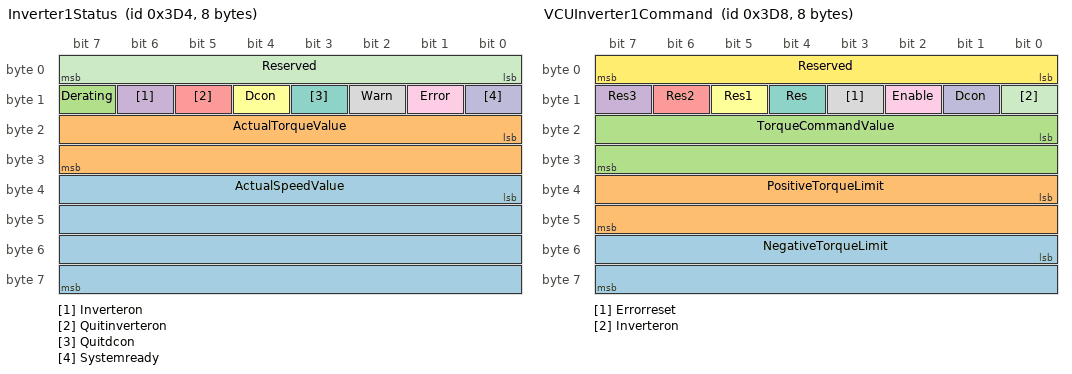
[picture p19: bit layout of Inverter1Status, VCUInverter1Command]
BO_ 980 Inverter1Status: 8 Vector__XXX
 SG_ ActualSpeedValue : 32|32@1- (0.001,0) [0|0] "rpm" Vector__XXX
 SG_ ActualTorqueValue : 16|16@1- (1,0) [0|0] "%MN" Vector__XXX
 SG_ Derating : 15|1@1+ (1,0) [0|0] "" Vector__XXX
 SG_ Inverteron : 14|1@1+ (1,0) [0|0] "" Vector__XXX
 SG_ Quitinverteron : 13|1@1+ (1,0) [0|0] "" Vector__XXX
 SG_ Dcon : 12|1@1+ (1,0) [0|0] "" Vector__XXX
 SG_ Quitdcon : 11|1@1+ (1,0) [0|0] "" Vector__XXX
 SG_ Warn : 10|1@1+ (1,0) [0|0] "" Vector__XXX
 SG_ Error : 9|1@1+ (1,0) [0|0] "" Vector__XXX
 SG_ Systemready : 8|1@1+ (1,0) [0|0] "" Vector__XXX
 SG_ Reserved : 0|8@1+ (1,0) [0|0] "" Vector__XXX

BO_ 981 Inverter1Temps: 8 Vector__XXX
 SG_ IdData : 48|16@1- (1,0) [0|0] "" Vector__XXX
 SG_ IqData : 32|16@1- (1,0) [0|0] "" Vector__XXX
 SG_ IGBTTemperature : 16|16@1- (0.1,0) [0|0] "DegC" Vector__XXX
 SG_ MotorTemperature : 0|16@1- (0.1,0) [0|0] "DegC" Vector__XXX

BO_ 982 Inverter1Error1: 8 Vector__XXX
 SG_ ErrorInfo1 : 32|32@1+ (1,0) [0|0] "" Vector__XXX
 SG_ DiagnosticNumber : 0|32@1+ (1,0) [0|0] "" Vector__XXX

BO_ 983 Inverter1Error2: 8 Vector__XXX
 SG_ ErrorInfo3 : 32|32@1+ (1,0) [0|0] "" Vector__XXX
 SG_ ErrorInfo2 : 0|32@1+ (1,0) [0|0] "" Vector__XXX

BO_ 984 VCUInverter1Command: 8 Vector__XXX
 SG_ NegativeTorqueLimit : 48|16@1- (1,0) [0|0] "%MN" Vector__XXX
 SG_ PositiveTorqueLimit : 32|16@1- (1,0) [0|0] "%MN" Vector__XXX
 SG_ TorqueCommandValue : 16|16@1- (1,0) [0|0] "%MN" Vector__XXX
 SG_ Res3 : 15|1@1+ (1,0) [0|0] "" Vector__XXX
 SG_ Res2 : 14|1@1+ (1,0) [0|0] "" Vector__XXX
 SG_ Res1 : 13|1@1+ (1,0) [0|0] "" Vector__XXX
 SG_ Res : 12|1@1+ (1,0) [0|0] "" Vector__XXX
 SG_ Errorreset : 11|1@1+ (1,0) [0|0] "" Vector__XXX
 SG_ Enable : 10|1@1+ (1,0) [0|0] "" Vector__XXX
 SG_ Dcon : 9|1@1+ (1,0) [0|0] "" Vector__XXX
 SG_ Inverteron : 8|1@1+ (1,0) [0|0] "" Vector__XXX
 SG_ Reserved : 0|8@1+ (1,0) [0|0] "" Vector__XXX

BO_ 464 TorqueEnable: 8 Vector__XXX
 SG_ TorqueEnable : 0|8@1+ (1,0) [0|0] "" Vector__XXX

BO_ 985 Inverter1DcvoltCurrentu: 8 Vector__XXX
 SG_ ActualCurrentPhaseU : 16|32@1+ (1,0) [0|0] "A" Vector__XXX
 SG_ DCVoltage : 0|16@1+ (1,0) [0|0] "V" Vector__XXX

BO_ 992 Inverter1Currentvw: 8 Vector__XXX
 SG_ ActualCurrentPhaseW : 32|32@1+ (1,0) [0|0] "A" Vector__XXX
 SG_ ActualCurrentPhaseV : 0|32@1+ (1,0) [0|0] "A" Vector__XXX
